VERSION "9"

NS_ :

BS_:

BU_: E115DCU

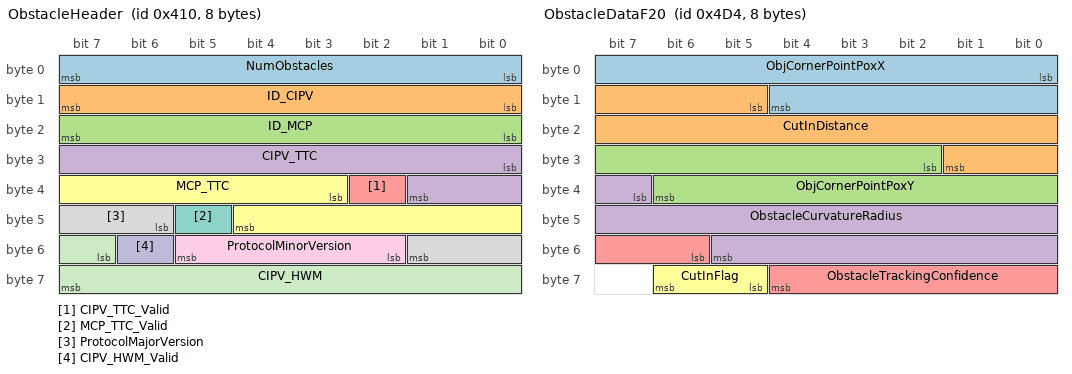
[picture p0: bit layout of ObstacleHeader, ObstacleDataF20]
BO_ 1040 ObstacleHeader: 8 E115DCU
 SG_ NumObstacles : 0|8@1+ (1,0) [0|20] "Counter" Vector__XXX
 SG_ ID_CIPV : 8|8@1+ (1,0) [0|255] "Counter" Vector__XXX
 SG_ ID_MCP : 16|8@1+ (1,0) [0|255] "Counter" Vector__XXX
 SG_ CIPV_TTC : 24|10@1+ (0.01,0) [0|10] "second" Vector__XXX
 SG_ CIPV_TTC_Valid : 34|1@1+ (1,0) [0|1] "bool" Vector__XXX
 SG_ MCP_TTC : 35|10@1+ (0.01,0) [0|10] "second" Vector__XXX
 SG_ MCP_TTC_Valid : 45|1@1+ (1,0) [0|1] "bool" Vector__XXX
 SG_ ProtocolMajorVersion : 46|4@1+ (1,0) [0|15] "Counter" Vector__XXX
 SG_ ProtocolMinorVersion : 50|4@1+ (1,0) [0|15] "Counter" Vector__XXX
 SG_ CIPV_HWM_Valid : 54|1@1+ (1,0) [0|1] "bool" Vector__XXX
 SG_ CIPV_HWM : 55|9@1+ (0.02,0) [0|10.22] "second" Vector__XXX

BO_ 1236 ObstacleDataF20: 8 Vector__XXX
 SG_ ObjCornerPointPoxX : 0|13@1+ (0.0625,-250) [-250|250] "m" Vector__XXX
 SG_ CutInDistance : 13|13@1+ (0.01,-40.96) [-40.96|40.95] "m" Vector__XXX
 SG_ ObjCornerPointPoxY : 26|13@1+ (0.0625,-250) [-250|250] "m" Vector__XXX
 SG_ ObstacleCurvatureRadius : 39|15@1+ (1,-9999) [-9999|9999] "m" Vector__XXX
 SG_ ObstacleTrackingConfidence : 54|7@1+ (1,0) [0|100] "prob" Vector__XXX
 SG_ CutInFlag : 61|2@1+ (1,0) [0|2] "Enum" Vector__XXX

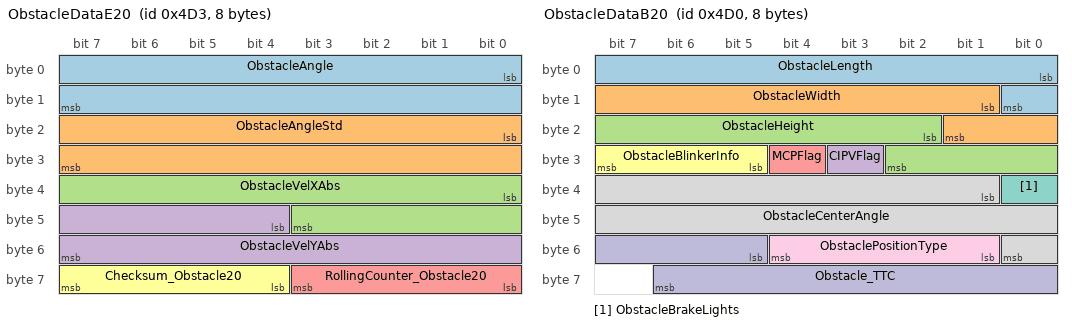
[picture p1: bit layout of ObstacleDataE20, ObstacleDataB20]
BO_ 1235 ObstacleDataE20: 8 E115DCU
 SG_ ObstacleAngle : 0|16@1+ (0.01,-327.68) [-327.68|327.67] "degree"  E115DCU
 SG_ ObstacleAngleStd : 16|16@1+ (0.01,0) [0|327.67] "degree"  E115DCU
 SG_ ObstacleVelXAbs : 32|12@1+ (0.05,-102.4) [-102.4|102.35] "m/sec"  E115DCU
 SG_ ObstacleVelYAbs : 44|12@1+ (0.05,-50) [-50|50] "m/sec"  E115DCU
 SG_ RollingCounter_Obstacle20 : 56|4@1+ (1,0) [0|15] "Counter"  E115DCU
 SG_ Checksum_Obstacle20 : 60|4@1+ (1,0) [0|15] "Counter"  E115DCU

BO_ 1234 ObstacleDataD20: 8 E115DCU
 SG_ ObstaclePosXSTD : 0|13@1+ (0.0625,0) [0|250] "m"  E115DCU
 SG_ ObstaclePosYSTD : 13|13@1+ (0.0625,0) [0|250] "m"  E115DCU
 SG_ ObstacleVelXSTD : 26|12@1+ (0.05,0) [0|102.35] "m/sec"  E115DCU
 SG_ ObstacleVelYSTD : 38|12@1+ (0.05,0) [0|50] "m/sec"  E115DCU
 SG_ ObstacleAccY : 50|10@1+ (0.03,-14.97) [-14.97|14.97] "m/s^2"  E115DCU

BO_ 1233 ObstacleDataC20: 8 E115DCU
 SG_ ObstaclePosX : 0|13@1+ (0.0625,-250) [-250|250] "m"  E115DCU
 SG_ ObstaclePosY : 13|13@1+ (0.0625,-250) [-250|250] "m"  E115DCU
 SG_ ObstacleVelX : 26|12@1+ (0.05,-102.4) [-102.4|102.35] "m/sec"  E115DCU
 SG_ ObstacleVelY : 38|12@1+ (0.05,-50) [-50|50] "m/sec"  E115DCU
 SG_ ObstacleAccX : 50|10@1+ (0.03,-14.97) [-14.97|14.97] "m/s^2"  E115DCU

BO_ 1232 ObstacleDataB20: 8 E115DCU
 SG_ ObstacleLength : 0|9@1+ (0.05,0) [0|25.6] "m"  E115DCU
 SG_ ObstacleWidth : 9|9@1+ (0.02,0) [0|10.24] "m"  E115DCU
 SG_ ObstacleHeight : 18|9@1+ (0.02,0) [0|10.24] "m"  E115DCU
 SG_ CIPVFlag : 27|1@1+ (1,0) [0|1] "bool"  E115DCU
 SG_ MCPFlag : 28|1@1+ (1,0) [0|1] "bool"  E115DCU
 SG_ ObstacleBlinkerInfo : 29|3@1+ (1,0) [0|4] "Enum"  E115DCU
 SG_ ObstacleBrakeLights : 32|1@1+ (1,0) [0|1] "bool"  E115DCU
 SG_ ObstacleCenterAngle : 33|16@1+ (0.01,-327.68) [-327.68|327.67] "degree"  E115DCU
 SG_ ObstaclePositionType : 49|4@1+ (1,0) [0|9] "Enum"  E115DCU
 SG_ Obstacle_TTC : 53|10@1+ (0.01,0) [0|10] "sec"  E115DCU

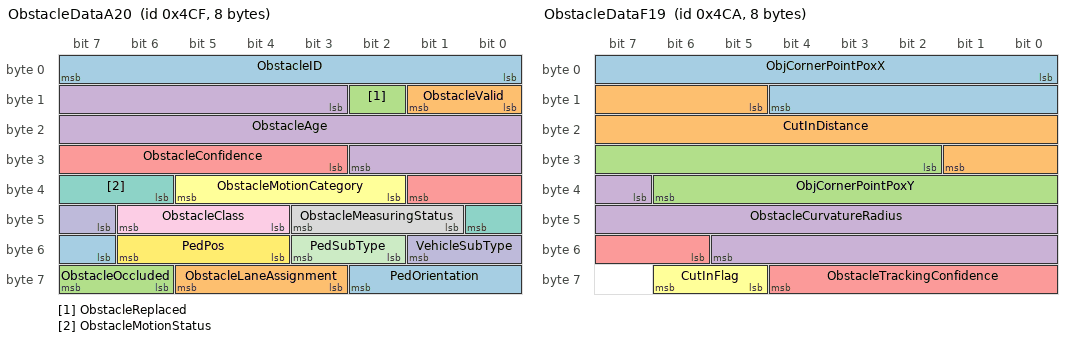
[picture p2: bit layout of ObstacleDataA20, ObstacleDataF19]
BO_ 1231 ObstacleDataA20: 8 E115DCU
 SG_ ObstacleID : 0|8@1+ (1,0) [0|255] "Counter"  E115DCU
 SG_ ObstacleValid : 8|2@1+ (1,0) [0|2] "Enum"  E115DCU
 SG_ ObstacleReplaced : 10|1@1+ (1,0) [0|1] "bool"  E115DCU
 SG_ ObstacleAge : 11|16@1+ (1,0) [0|65535] "Counter"  E115DCU
 SG_ ObstacleConfidence : 27|7@1+ (1,0) [0|100] "prob"  E115DCU
 SG_ ObstacleMotionCategory : 34|4@1+ (1,0) [0|13] "Enum"  E115DCU
 SG_ ObstacleMotionStatus : 38|3@1+ (1,0) [0|7] "Enum"  E115DCU
 SG_ ObstacleMeasuringStatus : 41|3@1+ (1,0) [0|7] "Enum"  E115DCU
 SG_ ObstacleClass : 44|3@1+ (1,0) [0|7] "Enum"  E115DCU
 SG_ VehicleSubType : 47|3@1+ (1,0) [0|7] "Enum"  E115DCU
 SG_ PedSubType : 50|2@1+ (1,0) [0|3] "Enum"  E115DCU
 SG_ PedPos : 52|3@1+ (1,0) [0|7] "Enum"  E115DCU
 SG_ PedOrientation : 55|4@1+ (1,0) [0|9] "Enum"  E115DCU
 SG_ ObstacleLaneAssignment : 59|3@1+ (1,0) [0|5] "Enum"  E115DCU
 SG_ ObstacleOccluded : 62|2@1+ (1,0) [0|3] "Enum"  E115DCU

BO_ 1226 ObstacleDataF19: 8 Vector__XXX
 SG_ ObjCornerPointPoxX : 0|13@1+ (0.0625,-250) [-250|250] "m" Vector__XXX
 SG_ CutInDistance : 13|13@1+ (0.01,-40.96) [-40.96|40.95] "m" Vector__XXX
 SG_ ObjCornerPointPoxY : 26|13@1+ (0.0625,-250) [-250|250] "m" Vector__XXX
 SG_ ObstacleCurvatureRadius : 39|15@1+ (1,-9999) [-9999|9999] "m" Vector__XXX
 SG_ ObstacleTrackingConfidence : 54|7@1+ (1,0) [0|100] "prob" Vector__XXX
 SG_ CutInFlag : 61|2@1+ (1,0) [0|2] "Enum" Vector__XXX

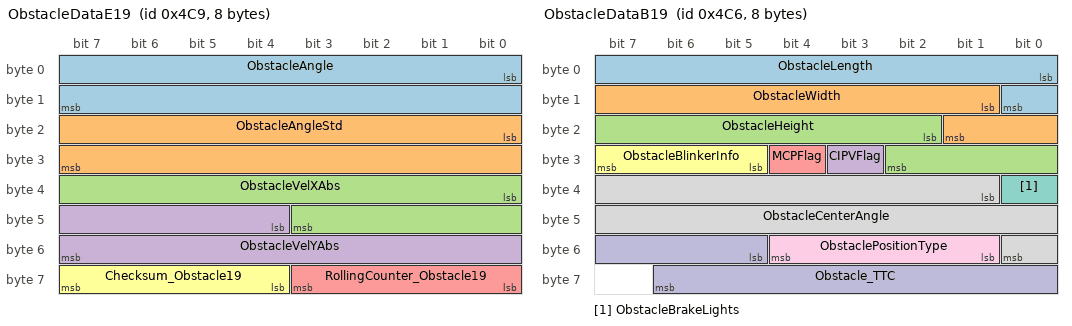
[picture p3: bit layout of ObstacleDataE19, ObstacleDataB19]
BO_ 1225 ObstacleDataE19: 8 E115DCU
 SG_ ObstacleAngle : 0|16@1+ (0.01,-327.68) [-327.68|327.67] "degree"  E115DCU
 SG_ ObstacleAngleStd : 16|16@1+ (0.01,0) [0|327.67] "degree"  E115DCU
 SG_ ObstacleVelXAbs : 32|12@1+ (0.05,-102.4) [-102.4|102.35] "m/sec"  E115DCU
 SG_ ObstacleVelYAbs : 44|12@1+ (0.05,-50) [-50|50] "m/sec"  E115DCU
 SG_ RollingCounter_Obstacle19 : 56|4@1+ (1,0) [0|15] "Counter"  E115DCU
 SG_ Checksum_Obstacle19 : 60|4@1+ (1,0) [0|15] "Counter"  E115DCU

BO_ 1224 ObstacleDataD19: 8 E115DCU
 SG_ ObstaclePosXSTD : 0|13@1+ (0.0625,0) [0|250] "m"  E115DCU
 SG_ ObstaclePosYSTD : 13|13@1+ (0.0625,0) [0|250] "m"  E115DCU
 SG_ ObstacleVelXSTD : 26|12@1+ (0.05,0) [0|102.35] "m/sec"  E115DCU
 SG_ ObstacleVelYSTD : 38|12@1+ (0.05,0) [0|50] "m/sec"  E115DCU
 SG_ ObstacleAccY : 50|10@1+ (0.03,-14.97) [-14.97|14.97] "m/s^2"  E115DCU

BO_ 1223 ObstacleDataC19: 8 E115DCU
 SG_ ObstaclePosX : 0|13@1+ (0.0625,-250) [-250|250] "m"  E115DCU
 SG_ ObstaclePosY : 13|13@1+ (0.0625,-250) [-250|250] "m"  E115DCU
 SG_ ObstacleVelX : 26|12@1+ (0.05,-102.4) [-102.4|102.35] "m/sec"  E115DCU
 SG_ ObstacleVelY : 38|12@1+ (0.05,-50) [-50|50] "m/sec"  E115DCU
 SG_ ObstacleAccX : 50|10@1+ (0.03,-14.97) [-14.97|14.97] "m/s^2"  E115DCU

BO_ 1222 ObstacleDataB19: 8 E115DCU
 SG_ ObstacleLength : 0|9@1+ (0.05,0) [0|25.6] "m"  E115DCU
 SG_ ObstacleWidth : 9|9@1+ (0.02,0) [0|10.24] "m"  E115DCU
 SG_ ObstacleHeight : 18|9@1+ (0.02,0) [0|10.24] "m"  E115DCU
 SG_ CIPVFlag : 27|1@1+ (1,0) [0|1] "bool"  E115DCU
 SG_ MCPFlag : 28|1@1+ (1,0) [0|1] "bool"  E115DCU
 SG_ ObstacleBlinkerInfo : 29|3@1+ (1,0) [0|4] "Enum"  E115DCU
 SG_ ObstacleBrakeLights : 32|1@1+ (1,0) [0|1] "bool"  E115DCU
 SG_ ObstacleCenterAngle : 33|16@1+ (0.01,-327.68) [-327.68|327.67] "degree"  E115DCU
 SG_ ObstaclePositionType : 49|4@1+ (1,0) [0|9] "Enum"  E115DCU
 SG_ Obstacle_TTC : 53|10@1+ (0.01,0) [0|10] "sec"  E115DCU

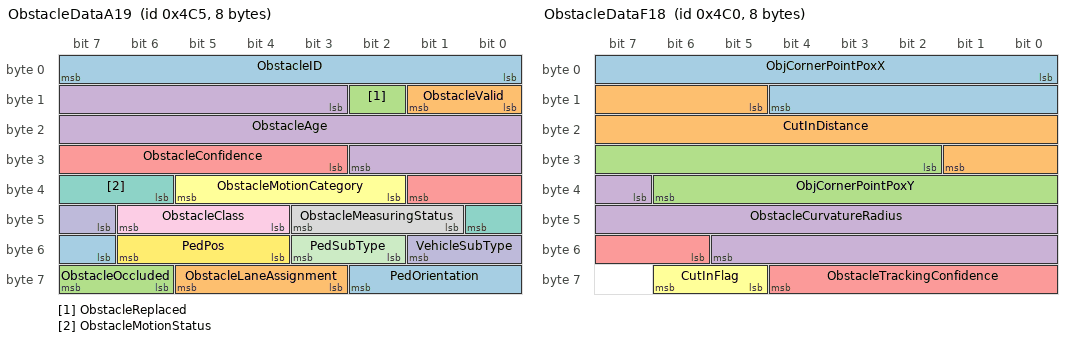
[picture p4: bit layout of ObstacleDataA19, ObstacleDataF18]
BO_ 1221 ObstacleDataA19: 8 E115DCU
 SG_ ObstacleID : 0|8@1+ (1,0) [0|255] "Counter"  E115DCU
 SG_ ObstacleValid : 8|2@1+ (1,0) [0|2] "Enum"  E115DCU
 SG_ ObstacleReplaced : 10|1@1+ (1,0) [0|1] "bool"  E115DCU
 SG_ ObstacleAge : 11|16@1+ (1,0) [0|65535] "Counter"  E115DCU
 SG_ ObstacleConfidence : 27|7@1+ (1,0) [0|100] "prob"  E115DCU
 SG_ ObstacleMotionCategory : 34|4@1+ (1,0) [0|13] "Enum"  E115DCU
 SG_ ObstacleMotionStatus : 38|3@1+ (1,0) [0|7] "Enum"  E115DCU
 SG_ ObstacleMeasuringStatus : 41|3@1+ (1,0) [0|7] "Enum"  E115DCU
 SG_ ObstacleClass : 44|3@1+ (1,0) [0|7] "Enum"  E115DCU
 SG_ VehicleSubType : 47|3@1+ (1,0) [0|7] "Enum"  E115DCU
 SG_ PedSubType : 50|2@1+ (1,0) [0|3] "Enum"  E115DCU
 SG_ PedPos : 52|3@1+ (1,0) [0|7] "Enum"  E115DCU
 SG_ PedOrientation : 55|4@1+ (1,0) [0|9] "Enum"  E115DCU
 SG_ ObstacleLaneAssignment : 59|3@1+ (1,0) [0|5] "Enum"  E115DCU
 SG_ ObstacleOccluded : 62|2@1+ (1,0) [0|3] "Enum"  E115DCU

BO_ 1216 ObstacleDataF18: 8 Vector__XXX
 SG_ ObjCornerPointPoxX : 0|13@1+ (0.0625,-250) [-250|250] "m" Vector__XXX
 SG_ CutInDistance : 13|13@1+ (0.01,-40.96) [-40.96|40.95] "m" Vector__XXX
 SG_ ObjCornerPointPoxY : 26|13@1+ (0.0625,-250) [-250|250] "m" Vector__XXX
 SG_ ObstacleCurvatureRadius : 39|15@1+ (1,-9999) [-9999|9999] "m" Vector__XXX
 SG_ ObstacleTrackingConfidence : 54|7@1+ (1,0) [0|100] "prob" Vector__XXX
 SG_ CutInFlag : 61|2@1+ (1,0) [0|2] "Enum" Vector__XXX

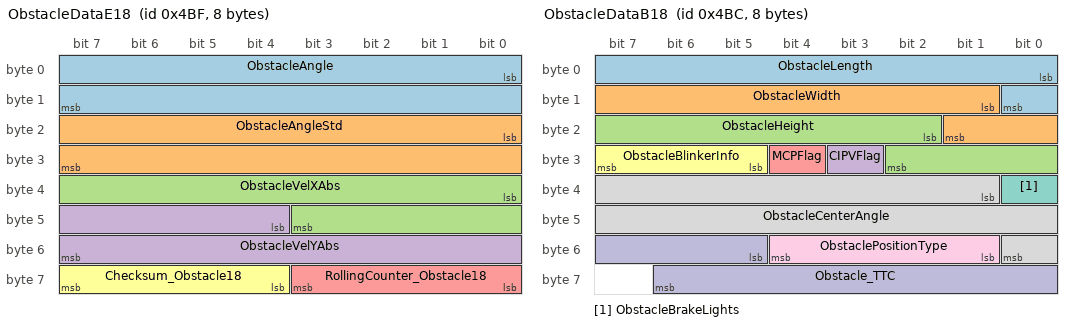
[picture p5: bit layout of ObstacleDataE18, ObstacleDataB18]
BO_ 1215 ObstacleDataE18: 8 E115DCU
 SG_ ObstacleAngle : 0|16@1+ (0.01,-327.68) [-327.68|327.67] "degree"  E115DCU
 SG_ ObstacleAngleStd : 16|16@1+ (0.01,0) [0|327.67] "degree"  E115DCU
 SG_ ObstacleVelXAbs : 32|12@1+ (0.05,-102.4) [-102.4|102.35] "m/sec"  E115DCU
 SG_ ObstacleVelYAbs : 44|12@1+ (0.05,-50) [-50|50] "m/sec"  E115DCU
 SG_ RollingCounter_Obstacle18 : 56|4@1+ (1,0) [0|15] "Counter"  E115DCU
 SG_ Checksum_Obstacle18 : 60|4@1+ (1,0) [0|15] "Counter"  E115DCU

BO_ 1214 ObstacleDataD18: 8 E115DCU
 SG_ ObstaclePosXSTD : 0|13@1+ (0.0625,0) [0|250] "m"  E115DCU
 SG_ ObstaclePosYSTD : 13|13@1+ (0.0625,0) [0|250] "m"  E115DCU
 SG_ ObstacleVelXSTD : 26|12@1+ (0.05,0) [0|102.35] "m/sec"  E115DCU
 SG_ ObstacleVelYSTD : 38|12@1+ (0.05,0) [0|50] "m/sec"  E115DCU
 SG_ ObstacleAccY : 50|10@1+ (0.03,-14.97) [-14.97|14.97] "m/s^2"  E115DCU

BO_ 1213 ObstacleDataC18: 8 E115DCU
 SG_ ObstaclePosX : 0|13@1+ (0.0625,-250) [-250|250] "m"  E115DCU
 SG_ ObstaclePosY : 13|13@1+ (0.0625,-250) [-250|250] "m"  E115DCU
 SG_ ObstacleVelX : 26|12@1+ (0.05,-102.4) [-102.4|102.35] "m/sec"  E115DCU
 SG_ ObstacleVelY : 38|12@1+ (0.05,-50) [-50|50] "m/sec"  E115DCU
 SG_ ObstacleAccX : 50|10@1+ (0.03,-14.97) [-14.97|14.97] "m/s^2"  E115DCU

BO_ 1212 ObstacleDataB18: 8 E115DCU
 SG_ ObstacleLength : 0|9@1+ (0.05,0) [0|25.6] "m"  E115DCU
 SG_ ObstacleWidth : 9|9@1+ (0.02,0) [0|10.24] "m"  E115DCU
 SG_ ObstacleHeight : 18|9@1+ (0.02,0) [0|10.24] "m"  E115DCU
 SG_ CIPVFlag : 27|1@1+ (1,0) [0|1] "bool"  E115DCU
 SG_ MCPFlag : 28|1@1+ (1,0) [0|1] "bool"  E115DCU
 SG_ ObstacleBlinkerInfo : 29|3@1+ (1,0) [0|4] "Enum"  E115DCU
 SG_ ObstacleBrakeLights : 32|1@1+ (1,0) [0|1] "bool"  E115DCU
 SG_ ObstacleCenterAngle : 33|16@1+ (0.01,-327.68) [-327.68|327.67] "degree"  E115DCU
 SG_ ObstaclePositionType : 49|4@1+ (1,0) [0|9] "Enum"  E115DCU
 SG_ Obstacle_TTC : 53|10@1+ (0.01,0) [0|10] "sec"  E115DCU

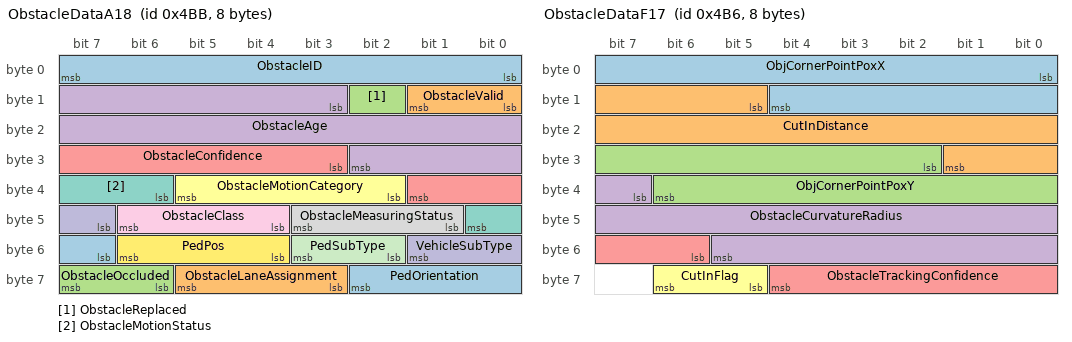
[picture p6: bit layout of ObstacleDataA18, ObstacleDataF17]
BO_ 1211 ObstacleDataA18: 8 E115DCU
 SG_ ObstacleID : 0|8@1+ (1,0) [0|255] "Counter"  E115DCU
 SG_ ObstacleValid : 8|2@1+ (1,0) [0|2] "Enum"  E115DCU
 SG_ ObstacleReplaced : 10|1@1+ (1,0) [0|1] "bool"  E115DCU
 SG_ ObstacleAge : 11|16@1+ (1,0) [0|65535] "Counter"  E115DCU
 SG_ ObstacleConfidence : 27|7@1+ (1,0) [0|100] "prob"  E115DCU
 SG_ ObstacleMotionCategory : 34|4@1+ (1,0) [0|13] "Enum"  E115DCU
 SG_ ObstacleMotionStatus : 38|3@1+ (1,0) [0|7] "Enum"  E115DCU
 SG_ ObstacleMeasuringStatus : 41|3@1+ (1,0) [0|7] "Enum"  E115DCU
 SG_ ObstacleClass : 44|3@1+ (1,0) [0|7] "Enum"  E115DCU
 SG_ VehicleSubType : 47|3@1+ (1,0) [0|7] "Enum"  E115DCU
 SG_ PedSubType : 50|2@1+ (1,0) [0|3] "Enum"  E115DCU
 SG_ PedPos : 52|3@1+ (1,0) [0|7] "Enum"  E115DCU
 SG_ PedOrientation : 55|4@1+ (1,0) [0|9] "Enum"  E115DCU
 SG_ ObstacleLaneAssignment : 59|3@1+ (1,0) [0|5] "Enum"  E115DCU
 SG_ ObstacleOccluded : 62|2@1+ (1,0) [0|3] "Enum"  E115DCU

BO_ 1206 ObstacleDataF17: 8 Vector__XXX
 SG_ ObjCornerPointPoxX : 0|13@1+ (0.0625,-250) [-250|250] "m" Vector__XXX
 SG_ CutInDistance : 13|13@1+ (0.01,-40.96) [-40.96|40.95] "m" Vector__XXX
 SG_ ObjCornerPointPoxY : 26|13@1+ (0.0625,-250) [-250|250] "m" Vector__XXX
 SG_ ObstacleCurvatureRadius : 39|15@1+ (1,-9999) [-9999|9999] "m" Vector__XXX
 SG_ ObstacleTrackingConfidence : 54|7@1+ (1,0) [0|100] "prob" Vector__XXX
 SG_ CutInFlag : 61|2@1+ (1,0) [0|2] "Enum" Vector__XXX

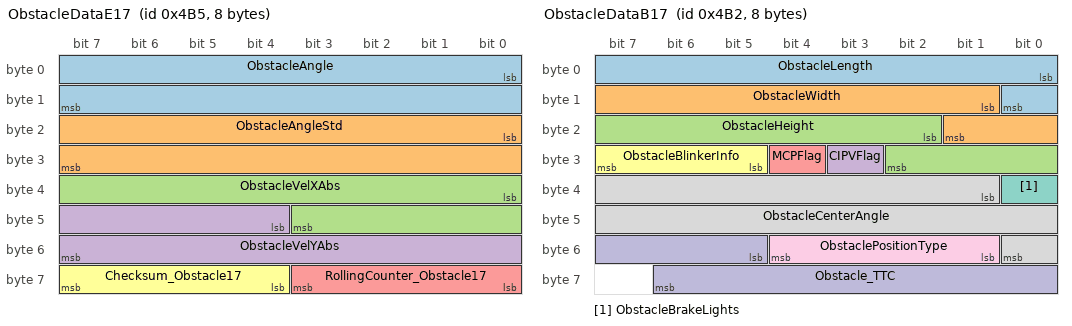
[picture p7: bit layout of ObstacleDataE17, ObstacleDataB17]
BO_ 1205 ObstacleDataE17: 8 E115DCU
 SG_ ObstacleAngle : 0|16@1+ (0.01,-327.68) [-327.68|327.67] "degree"  E115DCU
 SG_ ObstacleAngleStd : 16|16@1+ (0.01,0) [0|327.67] "degree"  E115DCU
 SG_ ObstacleVelXAbs : 32|12@1+ (0.05,-102.4) [-102.4|102.35] "m/sec"  E115DCU
 SG_ ObstacleVelYAbs : 44|12@1+ (0.05,-50) [-50|50] "m/sec"  E115DCU
 SG_ RollingCounter_Obstacle17 : 56|4@1+ (1,0) [0|15] "Counter"  E115DCU
 SG_ Checksum_Obstacle17 : 60|4@1+ (1,0) [0|15] "Counter"  E115DCU

BO_ 1204 ObstacleDataD17: 8 E115DCU
 SG_ ObstaclePosXSTD : 0|13@1+ (0.0625,0) [0|250] "m"  E115DCU
 SG_ ObstaclePosYSTD : 13|13@1+ (0.0625,0) [0|250] "m"  E115DCU
 SG_ ObstacleVelXSTD : 26|12@1+ (0.05,0) [0|102.35] "m/sec"  E115DCU
 SG_ ObstacleVelYSTD : 38|12@1+ (0.05,0) [0|50] "m/sec"  E115DCU
 SG_ ObstacleAccY : 50|10@1+ (0.03,-14.97) [-14.97|14.97] "m/s^2"  E115DCU

BO_ 1203 ObstacleDataC17: 8 E115DCU
 SG_ ObstaclePosX : 0|13@1+ (0.0625,-250) [-250|250] "m"  E115DCU
 SG_ ObstaclePosY : 13|13@1+ (0.0625,-250) [-250|250] "m"  E115DCU
 SG_ ObstacleVelX : 26|12@1+ (0.05,-102.4) [-102.4|102.35] "m/sec"  E115DCU
 SG_ ObstacleVelY : 38|12@1+ (0.05,-50) [-50|50] "m/sec"  E115DCU
 SG_ ObstacleAccX : 50|10@1+ (0.03,-14.97) [-14.97|14.97] "m/s^2"  E115DCU

BO_ 1202 ObstacleDataB17: 8 E115DCU
 SG_ ObstacleLength : 0|9@1+ (0.05,0) [0|25.6] "m"  E115DCU
 SG_ ObstacleWidth : 9|9@1+ (0.02,0) [0|10.24] "m"  E115DCU
 SG_ ObstacleHeight : 18|9@1+ (0.02,0) [0|10.24] "m"  E115DCU
 SG_ CIPVFlag : 27|1@1+ (1,0) [0|1] "bool"  E115DCU
 SG_ MCPFlag : 28|1@1+ (1,0) [0|1] "bool"  E115DCU
 SG_ ObstacleBlinkerInfo : 29|3@1+ (1,0) [0|4] "Enum"  E115DCU
 SG_ ObstacleBrakeLights : 32|1@1+ (1,0) [0|1] "bool"  E115DCU
 SG_ ObstacleCenterAngle : 33|16@1+ (0.01,-327.68) [-327.68|327.67] "degree"  E115DCU
 SG_ ObstaclePositionType : 49|4@1+ (1,0) [0|9] "Enum"  E115DCU
 SG_ Obstacle_TTC : 53|10@1+ (0.01,0) [0|10] "sec"  E115DCU

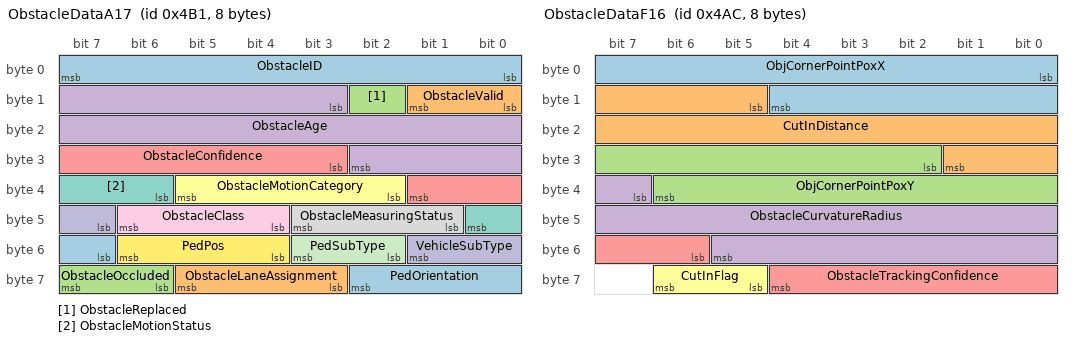
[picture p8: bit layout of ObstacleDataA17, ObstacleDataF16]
BO_ 1201 ObstacleDataA17: 8 E115DCU
 SG_ ObstacleID : 0|8@1+ (1,0) [0|255] "Counter"  E115DCU
 SG_ ObstacleValid : 8|2@1+ (1,0) [0|2] "Enum"  E115DCU
 SG_ ObstacleReplaced : 10|1@1+ (1,0) [0|1] "bool"  E115DCU
 SG_ ObstacleAge : 11|16@1+ (1,0) [0|65535] "Counter"  E115DCU
 SG_ ObstacleConfidence : 27|7@1+ (1,0) [0|100] "prob"  E115DCU
 SG_ ObstacleMotionCategory : 34|4@1+ (1,0) [0|13] "Enum"  E115DCU
 SG_ ObstacleMotionStatus : 38|3@1+ (1,0) [0|7] "Enum"  E115DCU
 SG_ ObstacleMeasuringStatus : 41|3@1+ (1,0) [0|7] "Enum"  E115DCU
 SG_ ObstacleClass : 44|3@1+ (1,0) [0|7] "Enum"  E115DCU
 SG_ VehicleSubType : 47|3@1+ (1,0) [0|7] "Enum"  E115DCU
 SG_ PedSubType : 50|2@1+ (1,0) [0|3] "Enum"  E115DCU
 SG_ PedPos : 52|3@1+ (1,0) [0|7] "Enum"  E115DCU
 SG_ PedOrientation : 55|4@1+ (1,0) [0|9] "Enum"  E115DCU
 SG_ ObstacleLaneAssignment : 59|3@1+ (1,0) [0|5] "Enum"  E115DCU
 SG_ ObstacleOccluded : 62|2@1+ (1,0) [0|3] "Enum"  E115DCU

BO_ 1196 ObstacleDataF16: 8 Vector__XXX
 SG_ ObjCornerPointPoxX : 0|13@1+ (0.0625,-250) [-250|250] "m" Vector__XXX
 SG_ CutInDistance : 13|13@1+ (0.01,-40.96) [-40.96|40.95] "m" Vector__XXX
 SG_ ObjCornerPointPoxY : 26|13@1+ (0.0625,-250) [-250|250] "m" Vector__XXX
 SG_ ObstacleCurvatureRadius : 39|15@1+ (1,-9999) [-9999|9999] "m" Vector__XXX
 SG_ ObstacleTrackingConfidence : 54|7@1+ (1,0) [0|100] "prob" Vector__XXX
 SG_ CutInFlag : 61|2@1+ (1,0) [0|2] "Enum" Vector__XXX

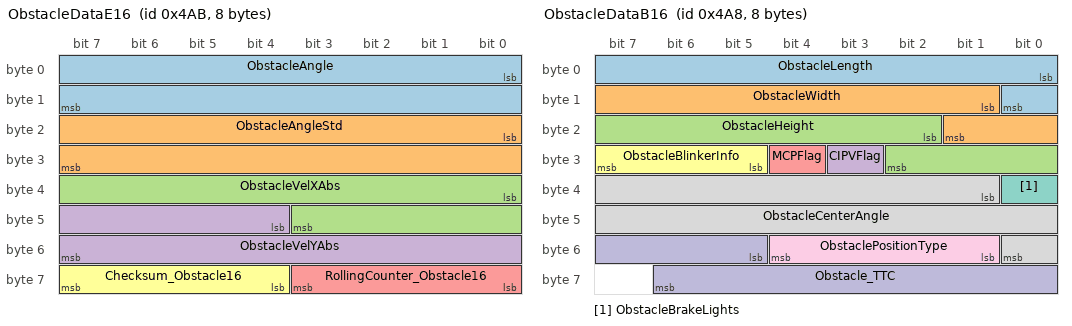
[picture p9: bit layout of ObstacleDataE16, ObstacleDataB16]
BO_ 1195 ObstacleDataE16: 8 E115DCU
 SG_ ObstacleAngle : 0|16@1+ (0.01,-327.68) [-327.68|327.67] "degree"  E115DCU
 SG_ ObstacleAngleStd : 16|16@1+ (0.01,0) [0|327.67] "degree"  E115DCU
 SG_ ObstacleVelXAbs : 32|12@1+ (0.05,-102.4) [-102.4|102.35] "m/sec"  E115DCU
 SG_ ObstacleVelYAbs : 44|12@1+ (0.05,-50) [-50|50] "m/sec"  E115DCU
 SG_ RollingCounter_Obstacle16 : 56|4@1+ (1,0) [0|15] "Counter"  E115DCU
 SG_ Checksum_Obstacle16 : 60|4@1+ (1,0) [0|15] "Counter"  E115DCU

BO_ 1194 ObstacleDataD16: 8 E115DCU
 SG_ ObstaclePosXSTD : 0|13@1+ (0.0625,0) [0|250] "m"  E115DCU
 SG_ ObstaclePosYSTD : 13|13@1+ (0.0625,0) [0|250] "m"  E115DCU
 SG_ ObstacleVelXSTD : 26|12@1+ (0.05,0) [0|102.35] "m/sec"  E115DCU
 SG_ ObstacleVelYSTD : 38|12@1+ (0.05,0) [0|50] "m/sec"  E115DCU
 SG_ ObstacleAccY : 50|10@1+ (0.03,-14.97) [-14.97|14.97] "m/s^2"  E115DCU

BO_ 1193 ObstacleDataC16: 8 E115DCU
 SG_ ObstaclePosX : 0|13@1+ (0.0625,-250) [-250|250] "m"  E115DCU
 SG_ ObstaclePosY : 13|13@1+ (0.0625,-250) [-250|250] "m"  E115DCU
 SG_ ObstacleVelX : 26|12@1+ (0.05,-102.4) [-102.4|102.35] "m/sec"  E115DCU
 SG_ ObstacleVelY : 38|12@1+ (0.05,-50) [-50|50] "m/sec"  E115DCU
 SG_ ObstacleAccX : 50|10@1+ (0.03,-14.97) [-14.97|14.97] "m/s^2"  E115DCU

BO_ 1192 ObstacleDataB16: 8 E115DCU
 SG_ ObstacleLength : 0|9@1+ (0.05,0) [0|25.6] "m"  E115DCU
 SG_ ObstacleWidth : 9|9@1+ (0.02,0) [0|10.24] "m"  E115DCU
 SG_ ObstacleHeight : 18|9@1+ (0.02,0) [0|10.24] "m"  E115DCU
 SG_ CIPVFlag : 27|1@1+ (1,0) [0|1] "bool"  E115DCU
 SG_ MCPFlag : 28|1@1+ (1,0) [0|1] "bool"  E115DCU
 SG_ ObstacleBlinkerInfo : 29|3@1+ (1,0) [0|4] "Enum"  E115DCU
 SG_ ObstacleBrakeLights : 32|1@1+ (1,0) [0|1] "bool"  E115DCU
 SG_ ObstacleCenterAngle : 33|16@1+ (0.01,-327.68) [-327.68|327.67] "degree"  E115DCU
 SG_ ObstaclePositionType : 49|4@1+ (1,0) [0|9] "Enum"  E115DCU
 SG_ Obstacle_TTC : 53|10@1+ (0.01,0) [0|10] "sec"  E115DCU

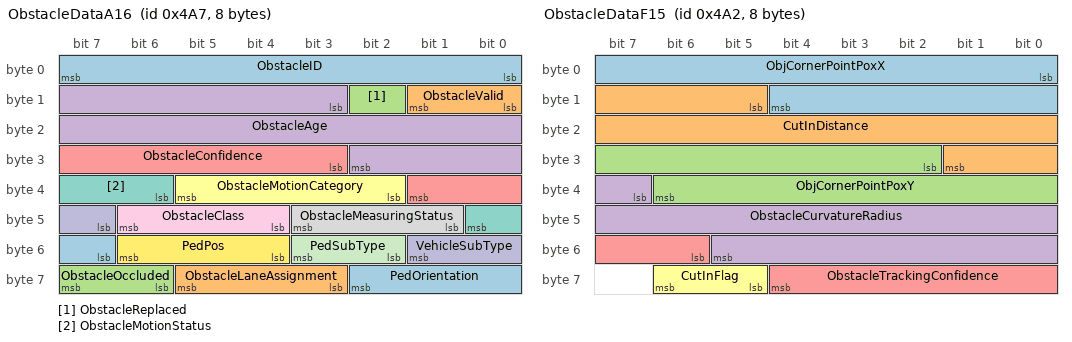
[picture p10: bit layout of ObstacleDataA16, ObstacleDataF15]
BO_ 1191 ObstacleDataA16: 8 E115DCU
 SG_ ObstacleID : 0|8@1+ (1,0) [0|255] "Counter"  E115DCU
 SG_ ObstacleValid : 8|2@1+ (1,0) [0|2] "Enum"  E115DCU
 SG_ ObstacleReplaced : 10|1@1+ (1,0) [0|1] "bool"  E115DCU
 SG_ ObstacleAge : 11|16@1+ (1,0) [0|65535] "Counter"  E115DCU
 SG_ ObstacleConfidence : 27|7@1+ (1,0) [0|100] "prob"  E115DCU
 SG_ ObstacleMotionCategory : 34|4@1+ (1,0) [0|13] "Enum"  E115DCU
 SG_ ObstacleMotionStatus : 38|3@1+ (1,0) [0|7] "Enum"  E115DCU
 SG_ ObstacleMeasuringStatus : 41|3@1+ (1,0) [0|7] "Enum"  E115DCU
 SG_ ObstacleClass : 44|3@1+ (1,0) [0|7] "Enum"  E115DCU
 SG_ VehicleSubType : 47|3@1+ (1,0) [0|7] "Enum"  E115DCU
 SG_ PedSubType : 50|2@1+ (1,0) [0|3] "Enum"  E115DCU
 SG_ PedPos : 52|3@1+ (1,0) [0|7] "Enum"  E115DCU
 SG_ PedOrientation : 55|4@1+ (1,0) [0|9] "Enum"  E115DCU
 SG_ ObstacleLaneAssignment : 59|3@1+ (1,0) [0|5] "Enum"  E115DCU
 SG_ ObstacleOccluded : 62|2@1+ (1,0) [0|3] "Enum"  E115DCU

BO_ 1186 ObstacleDataF15: 8 Vector__XXX
 SG_ ObjCornerPointPoxX : 0|13@1+ (0.0625,-250) [-250|250] "m" Vector__XXX
 SG_ CutInDistance : 13|13@1+ (0.01,-40.96) [-40.96|40.95] "m" Vector__XXX
 SG_ ObjCornerPointPoxY : 26|13@1+ (0.0625,-250) [-250|250] "m" Vector__XXX
 SG_ ObstacleCurvatureRadius : 39|15@1+ (1,-9999) [-9999|9999] "m" Vector__XXX
 SG_ ObstacleTrackingConfidence : 54|7@1+ (1,0) [0|100] "prob" Vector__XXX
 SG_ CutInFlag : 61|2@1+ (1,0) [0|2] "Enum" Vector__XXX

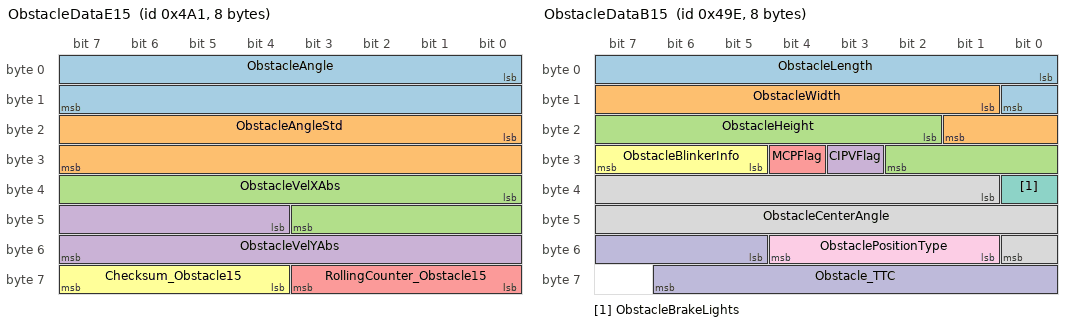
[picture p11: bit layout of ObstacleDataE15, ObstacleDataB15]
BO_ 1185 ObstacleDataE15: 8 E115DCU
 SG_ ObstacleAngle : 0|16@1+ (0.01,-327.68) [-327.68|327.67] "degree"  E115DCU
 SG_ ObstacleAngleStd : 16|16@1+ (0.01,0) [0|327.67] "degree"  E115DCU
 SG_ ObstacleVelXAbs : 32|12@1+ (0.05,-102.4) [-102.4|102.35] "m/sec"  E115DCU
 SG_ ObstacleVelYAbs : 44|12@1+ (0.05,-50) [-50|50] "m/sec"  E115DCU
 SG_ RollingCounter_Obstacle15 : 56|4@1+ (1,0) [0|15] "Counter"  E115DCU
 SG_ Checksum_Obstacle15 : 60|4@1+ (1,0) [0|15] "Counter"  E115DCU

BO_ 1184 ObstacleDataD15: 8 E115DCU
 SG_ ObstaclePosXSTD : 0|13@1+ (0.0625,0) [0|250] "m"  E115DCU
 SG_ ObstaclePosYSTD : 13|13@1+ (0.0625,0) [0|250] "m"  E115DCU
 SG_ ObstacleVelXSTD : 26|12@1+ (0.05,0) [0|102.35] "m/sec"  E115DCU
 SG_ ObstacleVelYSTD : 38|12@1+ (0.05,0) [0|50] "m/sec"  E115DCU
 SG_ ObstacleAccY : 50|10@1+ (0.03,-14.97) [-14.97|14.97] "m/s^2"  E115DCU

BO_ 1183 ObstacleDataC15: 8 E115DCU
 SG_ ObstaclePosX : 0|13@1+ (0.0625,-250) [-250|250] "m"  E115DCU
 SG_ ObstaclePosY : 13|13@1+ (0.0625,-250) [-250|250] "m"  E115DCU
 SG_ ObstacleVelX : 26|12@1+ (0.05,-102.4) [-102.4|102.35] "m/sec"  E115DCU
 SG_ ObstacleVelY : 38|12@1+ (0.05,-50) [-50|50] "m/sec"  E115DCU
 SG_ ObstacleAccX : 50|10@1+ (0.03,-14.97) [-14.97|14.97] "m/s^2"  E115DCU

BO_ 1182 ObstacleDataB15: 8 E115DCU
 SG_ ObstacleLength : 0|9@1+ (0.05,0) [0|25.6] "m"  E115DCU
 SG_ ObstacleWidth : 9|9@1+ (0.02,0) [0|10.24] "m"  E115DCU
 SG_ ObstacleHeight : 18|9@1+ (0.02,0) [0|10.24] "m"  E115DCU
 SG_ CIPVFlag : 27|1@1+ (1,0) [0|1] "bool"  E115DCU
 SG_ MCPFlag : 28|1@1+ (1,0) [0|1] "bool"  E115DCU
 SG_ ObstacleBlinkerInfo : 29|3@1+ (1,0) [0|4] "Enum"  E115DCU
 SG_ ObstacleBrakeLights : 32|1@1+ (1,0) [0|1] "bool"  E115DCU
 SG_ ObstacleCenterAngle : 33|16@1+ (0.01,-327.68) [-327.68|327.67] "degree"  E115DCU
 SG_ ObstaclePositionType : 49|4@1+ (1,0) [0|9] "Enum"  E115DCU
 SG_ Obstacle_TTC : 53|10@1+ (0.01,0) [0|10] "sec"  E115DCU

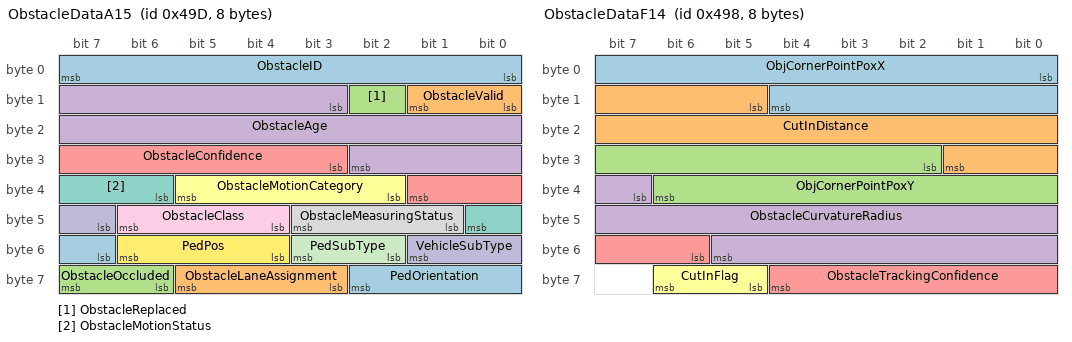
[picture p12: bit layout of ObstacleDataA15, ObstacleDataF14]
BO_ 1181 ObstacleDataA15: 8 E115DCU
 SG_ ObstacleID : 0|8@1+ (1,0) [0|255] "Counter"  E115DCU
 SG_ ObstacleValid : 8|2@1+ (1,0) [0|2] "Enum"  E115DCU
 SG_ ObstacleReplaced : 10|1@1+ (1,0) [0|1] "bool"  E115DCU
 SG_ ObstacleAge : 11|16@1+ (1,0) [0|65535] "Counter"  E115DCU
 SG_ ObstacleConfidence : 27|7@1+ (1,0) [0|100] "prob"  E115DCU
 SG_ ObstacleMotionCategory : 34|4@1+ (1,0) [0|13] "Enum"  E115DCU
 SG_ ObstacleMotionStatus : 38|3@1+ (1,0) [0|7] "Enum"  E115DCU
 SG_ ObstacleMeasuringStatus : 41|3@1+ (1,0) [0|7] "Enum"  E115DCU
 SG_ ObstacleClass : 44|3@1+ (1,0) [0|7] "Enum"  E115DCU
 SG_ VehicleSubType : 47|3@1+ (1,0) [0|7] "Enum"  E115DCU
 SG_ PedSubType : 50|2@1+ (1,0) [0|3] "Enum"  E115DCU
 SG_ PedPos : 52|3@1+ (1,0) [0|7] "Enum"  E115DCU
 SG_ PedOrientation : 55|4@1+ (1,0) [0|9] "Enum"  E115DCU
 SG_ ObstacleLaneAssignment : 59|3@1+ (1,0) [0|5] "Enum"  E115DCU
 SG_ ObstacleOccluded : 62|2@1+ (1,0) [0|3] "Enum"  E115DCU

BO_ 1176 ObstacleDataF14: 8 Vector__XXX
 SG_ ObjCornerPointPoxX : 0|13@1+ (0.0625,-250) [-250|250] "m" Vector__XXX
 SG_ CutInDistance : 13|13@1+ (0.01,-40.96) [-40.96|40.95] "m" Vector__XXX
 SG_ ObjCornerPointPoxY : 26|13@1+ (0.0625,-250) [-250|250] "m" Vector__XXX
 SG_ ObstacleCurvatureRadius : 39|15@1+ (1,-9999) [-9999|9999] "m" Vector__XXX
 SG_ ObstacleTrackingConfidence : 54|7@1+ (1,0) [0|100] "prob" Vector__XXX
 SG_ CutInFlag : 61|2@1+ (1,0) [0|2] "Enum" Vector__XXX

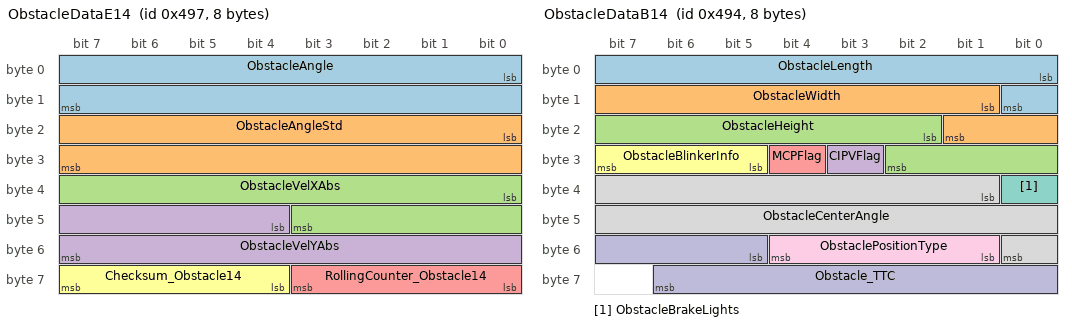
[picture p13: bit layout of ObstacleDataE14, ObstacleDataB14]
BO_ 1175 ObstacleDataE14: 8 E115DCU
 SG_ ObstacleAngle : 0|16@1+ (0.01,-327.68) [-327.68|327.67] "degree"  E115DCU
 SG_ ObstacleAngleStd : 16|16@1+ (0.01,0) [0|327.67] "degree"  E115DCU
 SG_ ObstacleVelXAbs : 32|12@1+ (0.05,-102.4) [-102.4|102.35] "m/sec"  E115DCU
 SG_ ObstacleVelYAbs : 44|12@1+ (0.05,-50) [-50|50] "m/sec"  E115DCU
 SG_ RollingCounter_Obstacle14 : 56|4@1+ (1,0) [0|15] "Counter"  E115DCU
 SG_ Checksum_Obstacle14 : 60|4@1+ (1,0) [0|15] "Counter"  E115DCU

BO_ 1174 ObstacleDataD14: 8 E115DCU
 SG_ ObstaclePosXSTD : 0|13@1+ (0.0625,0) [0|250] "m"  E115DCU
 SG_ ObstaclePosYSTD : 13|13@1+ (0.0625,0) [0|250] "m"  E115DCU
 SG_ ObstacleVelXSTD : 26|12@1+ (0.05,0) [0|102.35] "m/sec"  E115DCU
 SG_ ObstacleVelYSTD : 38|12@1+ (0.05,0) [0|50] "m/sec"  E115DCU
 SG_ ObstacleAccY : 50|10@1+ (0.03,-14.97) [-14.97|14.97] "m/s^2"  E115DCU

BO_ 1173 ObstacleDataC14: 8 E115DCU
 SG_ ObstaclePosX : 0|13@1+ (0.0625,-250) [-250|250] "m"  E115DCU
 SG_ ObstaclePosY : 13|13@1+ (0.0625,-250) [-250|250] "m"  E115DCU
 SG_ ObstacleVelX : 26|12@1+ (0.05,-102.4) [-102.4|102.35] "m/sec"  E115DCU
 SG_ ObstacleVelY : 38|12@1+ (0.05,-50) [-50|50] "m/sec"  E115DCU
 SG_ ObstacleAccX : 50|10@1+ (0.03,-14.97) [-14.97|14.97] "m/s^2"  E115DCU

BO_ 1172 ObstacleDataB14: 8 E115DCU
 SG_ ObstacleLength : 0|9@1+ (0.05,0) [0|25.6] "m"  E115DCU
 SG_ ObstacleWidth : 9|9@1+ (0.02,0) [0|10.24] "m"  E115DCU
 SG_ ObstacleHeight : 18|9@1+ (0.02,0) [0|10.24] "m"  E115DCU
 SG_ CIPVFlag : 27|1@1+ (1,0) [0|1] "bool"  E115DCU
 SG_ MCPFlag : 28|1@1+ (1,0) [0|1] "bool"  E115DCU
 SG_ ObstacleBlinkerInfo : 29|3@1+ (1,0) [0|4] "Enum"  E115DCU
 SG_ ObstacleBrakeLights : 32|1@1+ (1,0) [0|1] "bool"  E115DCU
 SG_ ObstacleCenterAngle : 33|16@1+ (0.01,-327.68) [-327.68|327.67] "degree"  E115DCU
 SG_ ObstaclePositionType : 49|4@1+ (1,0) [0|9] "Enum"  E115DCU
 SG_ Obstacle_TTC : 53|10@1+ (0.01,0) [0|10] "sec"  E115DCU

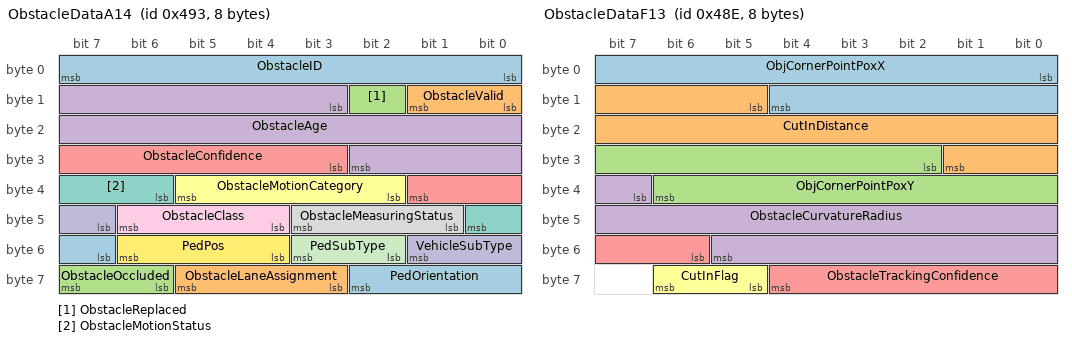
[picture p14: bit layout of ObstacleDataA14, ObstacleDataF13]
BO_ 1171 ObstacleDataA14: 8 E115DCU
 SG_ ObstacleID : 0|8@1+ (1,0) [0|255] "Counter"  E115DCU
 SG_ ObstacleValid : 8|2@1+ (1,0) [0|2] "Enum"  E115DCU
 SG_ ObstacleReplaced : 10|1@1+ (1,0) [0|1] "bool"  E115DCU
 SG_ ObstacleAge : 11|16@1+ (1,0) [0|65535] "Counter"  E115DCU
 SG_ ObstacleConfidence : 27|7@1+ (1,0) [0|100] "prob"  E115DCU
 SG_ ObstacleMotionCategory : 34|4@1+ (1,0) [0|13] "Enum"  E115DCU
 SG_ ObstacleMotionStatus : 38|3@1+ (1,0) [0|7] "Enum"  E115DCU
 SG_ ObstacleMeasuringStatus : 41|3@1+ (1,0) [0|7] "Enum"  E115DCU
 SG_ ObstacleClass : 44|3@1+ (1,0) [0|7] "Enum"  E115DCU
 SG_ VehicleSubType : 47|3@1+ (1,0) [0|7] "Enum"  E115DCU
 SG_ PedSubType : 50|2@1+ (1,0) [0|3] "Enum"  E115DCU
 SG_ PedPos : 52|3@1+ (1,0) [0|7] "Enum"  E115DCU
 SG_ PedOrientation : 55|4@1+ (1,0) [0|9] "Enum"  E115DCU
 SG_ ObstacleLaneAssignment : 59|3@1+ (1,0) [0|5] "Enum"  E115DCU
 SG_ ObstacleOccluded : 62|2@1+ (1,0) [0|3] "Enum"  E115DCU

BO_ 1166 ObstacleDataF13: 8 Vector__XXX
 SG_ ObjCornerPointPoxX : 0|13@1+ (0.0625,-250) [-250|250] "m" Vector__XXX
 SG_ CutInDistance : 13|13@1+ (0.01,-40.96) [-40.96|40.95] "m" Vector__XXX
 SG_ ObjCornerPointPoxY : 26|13@1+ (0.0625,-250) [-250|250] "m" Vector__XXX
 SG_ ObstacleCurvatureRadius : 39|15@1+ (1,-9999) [-9999|9999] "m" Vector__XXX
 SG_ ObstacleTrackingConfidence : 54|7@1+ (1,0) [0|100] "prob" Vector__XXX
 SG_ CutInFlag : 61|2@1+ (1,0) [0|2] "Enum" Vector__XXX

BO_ 1165 ObstacleDataE13: 8 E115DCU
 SG_ ObstacleAngle : 0|16@1+ (0.01,-327.68) [-327.68|327.67] "degree"  E115DCU
 SG_ ObstacleAngleStd : 16|16@1+ (0.01,0) [0|327.67] "degree"  E115DCU
 SG_ ObstacleVelXAbs : 32|12@1+ (0.05,-102.4) [-102.4|102.35] "m/sec"  E115DCU
 SG_ ObstacleVelYAbs : 44|12@1+ (0.05,-50) [-50|50] "m/sec"  E115DCU
 SG_ RollingCounter_Obstacle13 : 56|4@1+ (1,0) [0|15] "Counter"  E115DCU
 SG_ Checksum_Obstacle13 : 60|4@1+ (1,0) [0|15] "Counter"  E115DCU

BO_ 1164 ObstacleDataD13: 8 E115DCU
 SG_ ObstaclePosXSTD : 0|13@1+ (0.0625,0) [0|250] "m"  E115DCU
 SG_ ObstaclePosYSTD : 13|13@1+ (0.0625,0) [0|250] "m"  E115DCU
 SG_ ObstacleVelXSTD : 26|12@1+ (0.05,0) [0|102.35] "m/sec"  E115DCU
 SG_ ObstacleVelYSTD : 38|12@1+ (0.05,0) [0|50] "m/sec"  E115DCU
 SG_ ObstacleAccY : 50|10@1+ (0.03,-14.97) [-14.97|14.97] "m/s^2"  E115DCU

BO_ 1163 ObstacleDataC13: 8 E115DCU
 SG_ ObstaclePosX : 0|13@1+ (0.0625,-250) [-250|250] "m"  E115DCU
 SG_ ObstaclePosY : 13|13@1+ (0.0625,-250) [-250|250] "m"  E115DCU
 SG_ ObstacleVelX : 26|12@1+ (0.05,-102.4) [-102.4|102.35] "m/sec"  E115DCU
 SG_ ObstacleVelY : 38|12@1+ (0.05,-50) [-50|50] "m/sec"  E115DCU
 SG_ ObstacleAccX : 50|10@1+ (0.03,-14.97) [-14.97|14.97] "m/s^2"  E115DCU

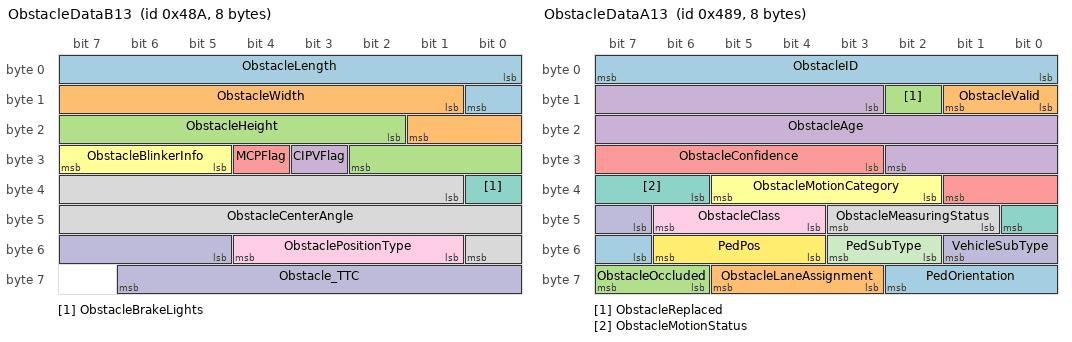
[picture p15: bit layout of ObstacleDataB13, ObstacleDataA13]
BO_ 1162 ObstacleDataB13: 8 E115DCU
 SG_ ObstacleLength : 0|9@1+ (0.05,0) [0|25.6] "m"  E115DCU
 SG_ ObstacleWidth : 9|9@1+ (0.02,0) [0|10.24] "m"  E115DCU
 SG_ ObstacleHeight : 18|9@1+ (0.02,0) [0|10.24] "m"  E115DCU
 SG_ CIPVFlag : 27|1@1+ (1,0) [0|1] "bool"  E115DCU
 SG_ MCPFlag : 28|1@1+ (1,0) [0|1] "bool"  E115DCU
 SG_ ObstacleBlinkerInfo : 29|3@1+ (1,0) [0|4] "Enum"  E115DCU
 SG_ ObstacleBrakeLights : 32|1@1+ (1,0) [0|1] "bool"  E115DCU
 SG_ ObstacleCenterAngle : 33|16@1+ (0.01,-327.68) [-327.68|327.67] "degree"  E115DCU
 SG_ ObstaclePositionType : 49|4@1+ (1,0) [0|9] "Enum"  E115DCU
 SG_ Obstacle_TTC : 53|10@1+ (0.01,0) [0|10] "sec"  E115DCU

BO_ 1161 ObstacleDataA13: 8 E115DCU
 SG_ ObstacleID : 0|8@1+ (1,0) [0|255] "Counter"  E115DCU
 SG_ ObstacleValid : 8|2@1+ (1,0) [0|2] "Enum"  E115DCU
 SG_ ObstacleReplaced : 10|1@1+ (1,0) [0|1] "bool"  E115DCU
 SG_ ObstacleAge : 11|16@1+ (1,0) [0|65535] "Counter"  E115DCU
 SG_ ObstacleConfidence : 27|7@1+ (1,0) [0|100] "prob"  E115DCU
 SG_ ObstacleMotionCategory : 34|4@1+ (1,0) [0|13] "Enum"  E115DCU
 SG_ ObstacleMotionStatus : 38|3@1+ (1,0) [0|7] "Enum"  E115DCU
 SG_ ObstacleMeasuringStatus : 41|3@1+ (1,0) [0|7] "Enum"  E115DCU
 SG_ ObstacleClass : 44|3@1+ (1,0) [0|7] "Enum"  E115DCU
 SG_ VehicleSubType : 47|3@1+ (1,0) [0|7] "Enum"  E115DCU
 SG_ PedSubType : 50|2@1+ (1,0) [0|3] "Enum"  E115DCU
 SG_ PedPos : 52|3@1+ (1,0) [0|7] "Enum"  E115DCU
 SG_ PedOrientation : 55|4@1+ (1,0) [0|9] "Enum"  E115DCU
 SG_ ObstacleLaneAssignment : 59|3@1+ (1,0) [0|5] "Enum"  E115DCU
 SG_ ObstacleOccluded : 62|2@1+ (1,0) [0|3] "Enum"  E115DCU

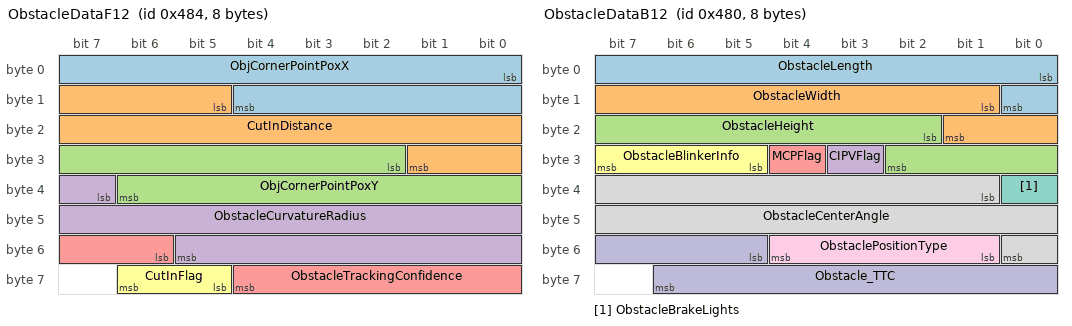
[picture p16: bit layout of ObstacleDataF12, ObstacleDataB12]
BO_ 1156 ObstacleDataF12: 8 Vector__XXX
 SG_ ObjCornerPointPoxX : 0|13@1+ (0.0625,-250) [-250|250] "m" Vector__XXX
 SG_ CutInDistance : 13|13@1+ (0.01,-40.96) [-40.96|40.95] "m" Vector__XXX
 SG_ ObjCornerPointPoxY : 26|13@1+ (0.0625,-250) [-250|250] "m" Vector__XXX
 SG_ ObstacleCurvatureRadius : 39|15@1+ (1,-9999) [-9999|9999] "m" Vector__XXX
 SG_ ObstacleTrackingConfidence : 54|7@1+ (1,0) [0|100] "prob" Vector__XXX
 SG_ CutInFlag : 61|2@1+ (1,0) [0|2] "Enum" Vector__XXX

BO_ 1155 ObstacleDataE12: 8 E115DCU
 SG_ ObstacleAngle : 0|16@1+ (0.01,-327.68) [-327.68|327.67] "degree"  E115DCU
 SG_ ObstacleAngleStd : 16|16@1+ (0.01,0) [0|327.67] "degree"  E115DCU
 SG_ ObstacleVelXAbs : 32|12@1+ (0.05,-102.4) [-102.4|102.35] "m/sec"  E115DCU
 SG_ ObstacleVelYAbs : 44|12@1+ (0.05,-50) [-50|50] "m/sec"  E115DCU
 SG_ RollingCounter_Obstacle12 : 56|4@1+ (1,0) [0|15] "Counter"  E115DCU
 SG_ Checksum_Obstacle12 : 60|4@1+ (1,0) [0|15] "Counter"  E115DCU

BO_ 1154 ObstacleDataD12: 8 E115DCU
 SG_ ObstaclePosXSTD : 0|13@1+ (0.0625,0) [0|250] "m"  E115DCU
 SG_ ObstaclePosYSTD : 13|13@1+ (0.0625,0) [0|250] "m"  E115DCU
 SG_ ObstacleVelXSTD : 26|12@1+ (0.05,0) [0|102.35] "m/sec"  E115DCU
 SG_ ObstacleVelYSTD : 38|12@1+ (0.05,0) [0|50] "m/sec"  E115DCU
 SG_ ObstacleAccY : 50|10@1+ (0.03,-14.97) [-14.97|14.97] "m/s^2"  E115DCU

BO_ 1153 ObstacleDataC12: 8 E115DCU
 SG_ ObstaclePosX : 0|13@1+ (0.0625,-250) [-250|250] "m"  E115DCU
 SG_ ObstaclePosY : 13|13@1+ (0.0625,-250) [-250|250] "m"  E115DCU
 SG_ ObstacleVelX : 26|12@1+ (0.05,-102.4) [-102.4|102.35] "m/sec"  E115DCU
 SG_ ObstacleVelY : 38|12@1+ (0.05,-50) [-50|50] "m/sec"  E115DCU
 SG_ ObstacleAccX : 50|10@1+ (0.03,-14.97) [-14.97|14.97] "m/s^2"  E115DCU

BO_ 1152 ObstacleDataB12: 8 E115DCU
 SG_ ObstacleLength : 0|9@1+ (0.05,0) [0|25.6] "m"  E115DCU
 SG_ ObstacleWidth : 9|9@1+ (0.02,0) [0|10.24] "m"  E115DCU
 SG_ ObstacleHeight : 18|9@1+ (0.02,0) [0|10.24] "m"  E115DCU
 SG_ CIPVFlag : 27|1@1+ (1,0) [0|1] "bool"  E115DCU
 SG_ MCPFlag : 28|1@1+ (1,0) [0|1] "bool"  E115DCU
 SG_ ObstacleBlinkerInfo : 29|3@1+ (1,0) [0|4] "Enum"  E115DCU
 SG_ ObstacleBrakeLights : 32|1@1+ (1,0) [0|1] "bool"  E115DCU
 SG_ ObstacleCenterAngle : 33|16@1+ (0.01,-327.68) [-327.68|327.67] "degree"  E115DCU
 SG_ ObstaclePositionType : 49|4@1+ (1,0) [0|9] "Enum"  E115DCU
 SG_ Obstacle_TTC : 53|10@1+ (0.01,0) [0|10] "sec"  E115DCU

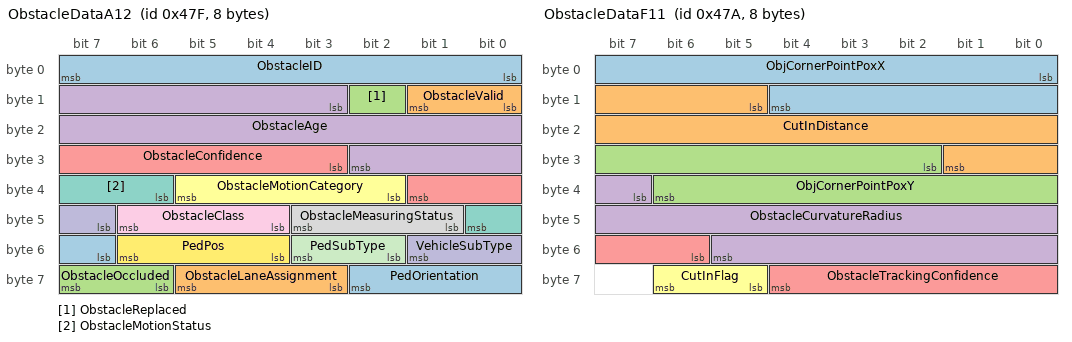
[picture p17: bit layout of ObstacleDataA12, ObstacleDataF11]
BO_ 1151 ObstacleDataA12: 8 E115DCU
 SG_ ObstacleID : 0|8@1+ (1,0) [0|255] "Counter"  E115DCU
 SG_ ObstacleValid : 8|2@1+ (1,0) [0|2] "Enum"  E115DCU
 SG_ ObstacleReplaced : 10|1@1+ (1,0) [0|1] "bool"  E115DCU
 SG_ ObstacleAge : 11|16@1+ (1,0) [0|65535] "Counter"  E115DCU
 SG_ ObstacleConfidence : 27|7@1+ (1,0) [0|100] "prob"  E115DCU
 SG_ ObstacleMotionCategory : 34|4@1+ (1,0) [0|13] "Enum"  E115DCU
 SG_ ObstacleMotionStatus : 38|3@1+ (1,0) [0|7] "Enum"  E115DCU
 SG_ ObstacleMeasuringStatus : 41|3@1+ (1,0) [0|7] "Enum"  E115DCU
 SG_ ObstacleClass : 44|3@1+ (1,0) [0|7] "Enum"  E115DCU
 SG_ VehicleSubType : 47|3@1+ (1,0) [0|7] "Enum"  E115DCU
 SG_ PedSubType : 50|2@1+ (1,0) [0|3] "Enum"  E115DCU
 SG_ PedPos : 52|3@1+ (1,0) [0|7] "Enum"  E115DCU
 SG_ PedOrientation : 55|4@1+ (1,0) [0|9] "Enum"  E115DCU
 SG_ ObstacleLaneAssignment : 59|3@1+ (1,0) [0|5] "Enum"  E115DCU
 SG_ ObstacleOccluded : 62|2@1+ (1,0) [0|3] "Enum"  E115DCU

BO_ 1146 ObstacleDataF11: 8 Vector__XXX
 SG_ ObjCornerPointPoxX : 0|13@1+ (0.0625,-250) [-250|250] "m" Vector__XXX
 SG_ CutInDistance : 13|13@1+ (0.01,-40.96) [-40.96|40.95] "m" Vector__XXX
 SG_ ObjCornerPointPoxY : 26|13@1+ (0.0625,-250) [-250|250] "m" Vector__XXX
 SG_ ObstacleCurvatureRadius : 39|15@1+ (1,-9999) [-9999|9999] "m" Vector__XXX
 SG_ ObstacleTrackingConfidence : 54|7@1+ (1,0) [0|100] "prob" Vector__XXX
 SG_ CutInFlag : 61|2@1+ (1,0) [0|2] "Enum" Vector__XXX

BO_ 1145 ObstacleDataE11: 8 E115DCU
 SG_ ObstacleAngle : 0|16@1+ (0.01,-327.68) [-327.68|327.67] "degree"  E115DCU
 SG_ ObstacleAngleStd : 16|16@1+ (0.01,0) [0|327.67] "degree"  E115DCU
 SG_ ObstacleVelXAbs : 32|12@1+ (0.05,-102.4) [-102.4|102.35] "m/sec"  E115DCU
 SG_ ObstacleVelYAbs : 44|12@1+ (0.05,-50) [-50|50] "m/sec"  E115DCU
 SG_ RollingCounter_Obstacle11 : 56|4@1+ (1,0) [0|15] "Counter"  E115DCU
 SG_ Checksum_Obstacle11 : 60|4@1+ (1,0) [0|15] "Counter"  E115DCU

BO_ 1144 ObstacleDataD11: 8 E115DCU
 SG_ ObstaclePosXSTD : 0|13@1+ (0.0625,0) [0|250] "m"  E115DCU
 SG_ ObstaclePosYSTD : 13|13@1+ (0.0625,0) [0|250] "m"  E115DCU
 SG_ ObstacleVelXSTD : 26|12@1+ (0.05,0) [0|102.35] "m/sec"  E115DCU
 SG_ ObstacleVelYSTD : 38|12@1+ (0.05,0) [0|50] "m/sec"  E115DCU
 SG_ ObstacleAccY : 50|10@1+ (0.03,-14.97) [-14.97|14.97] "m/s^2"  E115DCU

BO_ 1143 ObstacleDataC11: 8 E115DCU
 SG_ ObstaclePosX : 0|13@1+ (0.0625,-250) [-250|250] "m"  E115DCU
 SG_ ObstaclePosY : 13|13@1+ (0.0625,-250) [-250|250] "m"  E115DCU
 SG_ ObstacleVelX : 26|12@1+ (0.05,-102.4) [-102.4|102.35] "m/sec"  E115DCU
 SG_ ObstacleVelY : 38|12@1+ (0.05,-50) [-50|50] "m/sec"  E115DCU
 SG_ ObstacleAccX : 50|10@1+ (0.03,-14.97) [-14.97|14.97] "m/s^2"  E115DCU

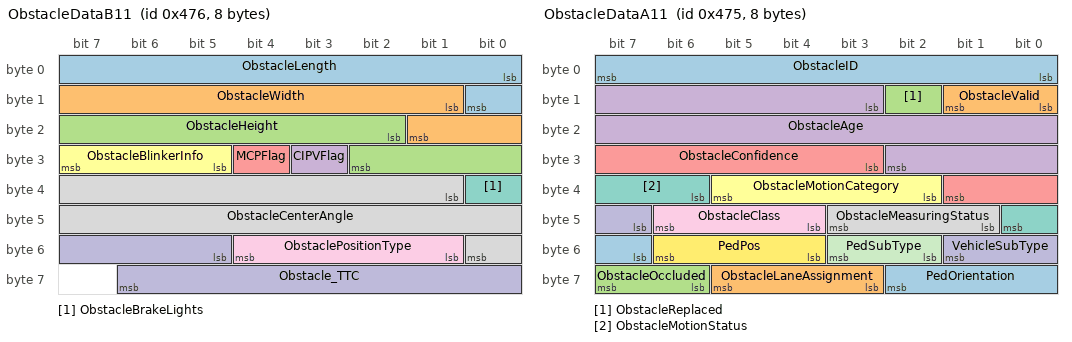
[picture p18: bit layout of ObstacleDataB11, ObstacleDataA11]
BO_ 1142 ObstacleDataB11: 8 E115DCU
 SG_ ObstacleLength : 0|9@1+ (0.05,0) [0|25.6] "m"  E115DCU
 SG_ ObstacleWidth : 9|9@1+ (0.02,0) [0|10.24] "m"  E115DCU
 SG_ ObstacleHeight : 18|9@1+ (0.02,0) [0|10.24] "m"  E115DCU
 SG_ CIPVFlag : 27|1@1+ (1,0) [0|1] "bool"  E115DCU
 SG_ MCPFlag : 28|1@1+ (1,0) [0|1] "bool"  E115DCU
 SG_ ObstacleBlinkerInfo : 29|3@1+ (1,0) [0|4] "Enum"  E115DCU
 SG_ ObstacleBrakeLights : 32|1@1+ (1,0) [0|1] "bool"  E115DCU
 SG_ ObstacleCenterAngle : 33|16@1+ (0.01,-327.68) [-327.68|327.67] "degree"  E115DCU
 SG_ ObstaclePositionType : 49|4@1+ (1,0) [0|9] "Enum"  E115DCU
 SG_ Obstacle_TTC : 53|10@1+ (0.01,0) [0|10] "sec"  E115DCU

BO_ 1141 ObstacleDataA11: 8 E115DCU
 SG_ ObstacleID : 0|8@1+ (1,0) [0|255] "Counter"  E115DCU
 SG_ ObstacleValid : 8|2@1+ (1,0) [0|2] "Enum"  E115DCU
 SG_ ObstacleReplaced : 10|1@1+ (1,0) [0|1] "bool"  E115DCU
 SG_ ObstacleAge : 11|16@1+ (1,0) [0|65535] "Counter"  E115DCU
 SG_ ObstacleConfidence : 27|7@1+ (1,0) [0|100] "prob"  E115DCU
 SG_ ObstacleMotionCategory : 34|4@1+ (1,0) [0|13] "Enum"  E115DCU
 SG_ ObstacleMotionStatus : 38|3@1+ (1,0) [0|7] "Enum"  E115DCU
 SG_ ObstacleMeasuringStatus : 41|3@1+ (1,0) [0|7] "Enum"  E115DCU
 SG_ ObstacleClass : 44|3@1+ (1,0) [0|7] "Enum"  E115DCU
 SG_ VehicleSubType : 47|3@1+ (1,0) [0|7] "Enum"  E115DCU
 SG_ PedSubType : 50|2@1+ (1,0) [0|3] "Enum"  E115DCU
 SG_ PedPos : 52|3@1+ (1,0) [0|7] "Enum"  E115DCU
 SG_ PedOrientation : 55|4@1+ (1,0) [0|9] "Enum"  E115DCU
 SG_ ObstacleLaneAssignment : 59|3@1+ (1,0) [0|5] "Enum"  E115DCU
 SG_ ObstacleOccluded : 62|2@1+ (1,0) [0|3] "Enum"  E115DCU

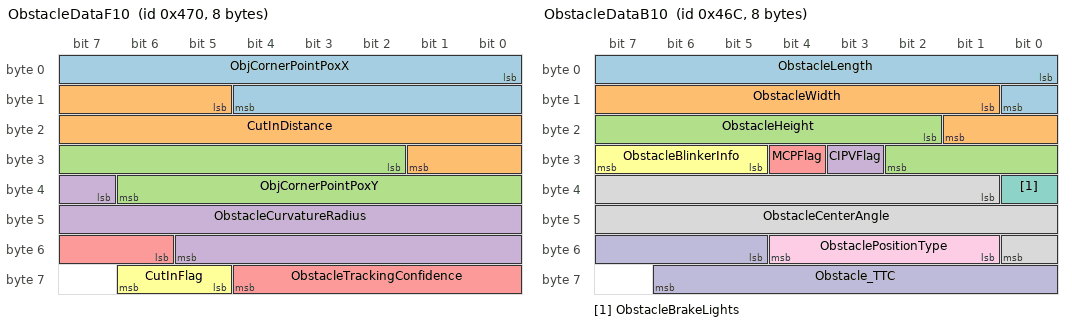
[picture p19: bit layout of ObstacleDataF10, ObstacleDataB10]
BO_ 1136 ObstacleDataF10: 8 Vector__XXX
 SG_ ObjCornerPointPoxX : 0|13@1+ (0.0625,-250) [-250|250] "m" Vector__XXX
 SG_ CutInDistance : 13|13@1+ (0.01,-40.96) [-40.96|40.95] "m" Vector__XXX
 SG_ ObjCornerPointPoxY : 26|13@1+ (0.0625,-250) [-250|250] "m" Vector__XXX
 SG_ ObstacleCurvatureRadius : 39|15@1+ (1,-9999) [-9999|9999] "m" Vector__XXX
 SG_ ObstacleTrackingConfidence : 54|7@1+ (1,0) [0|100] "prob" Vector__XXX
 SG_ CutInFlag : 61|2@1+ (1,0) [0|2] "Enum" Vector__XXX

BO_ 1135 ObstacleDataE10: 8 E115DCU
 SG_ ObstacleAngle : 0|16@1+ (0.01,-327.68) [-327.68|327.67] "degree"  E115DCU
 SG_ ObstacleAngleStd : 16|16@1+ (0.01,0) [0|327.67] "degree"  E115DCU
 SG_ ObstacleVelXAbs : 32|12@1+ (0.05,-102.4) [-102.4|102.35] "m/sec"  E115DCU
 SG_ ObstacleVelYAbs : 44|12@1+ (0.05,-50) [-50|50] "m/sec"  E115DCU
 SG_ RollingCounter_Obstacle10 : 56|4@1+ (1,0) [0|15] "Counter"  E115DCU
 SG_ Checksum_Obstacle10 : 60|4@1+ (1,0) [0|15] "Counter"  E115DCU

BO_ 1134 ObstacleDataD10: 8 E115DCU
 SG_ ObstaclePosXSTD : 0|13@1+ (0.0625,0) [0|250] "m"  E115DCU
 SG_ ObstaclePosYSTD : 13|13@1+ (0.0625,0) [0|250] "m"  E115DCU
 SG_ ObstacleVelXSTD : 26|12@1+ (0.05,0) [0|102.35] "m/sec"  E115DCU
 SG_ ObstacleVelYSTD : 38|12@1+ (0.05,0) [0|50] "m/sec"  E115DCU
 SG_ ObstacleAccY : 50|10@1+ (0.03,-14.97) [-14.97|14.97] "m/s^2"  E115DCU

BO_ 1133 ObstacleDataC10: 8 E115DCU
 SG_ ObstaclePosX : 0|13@1+ (0.0625,-250) [-250|250] "m"  E115DCU
 SG_ ObstaclePosY : 13|13@1+ (0.0625,-250) [-250|250] "m"  E115DCU
 SG_ ObstacleVelX : 26|12@1+ (0.05,-102.4) [-102.4|102.35] "m/sec"  E115DCU
 SG_ ObstacleVelY : 38|12@1+ (0.05,-50) [-50|50] "m/sec"  E115DCU
 SG_ ObstacleAccX : 50|10@1+ (0.03,-14.97) [-14.97|14.97] "m/s^2"  E115DCU

BO_ 1132 ObstacleDataB10: 8 E115DCU
 SG_ ObstacleLength : 0|9@1+ (0.05,0) [0|25.6] "m"  E115DCU
 SG_ ObstacleWidth : 9|9@1+ (0.02,0) [0|10.24] "m"  E115DCU
 SG_ ObstacleHeight : 18|9@1+ (0.02,0) [0|10.24] "m"  E115DCU
 SG_ CIPVFlag : 27|1@1+ (1,0) [0|1] "bool"  E115DCU
 SG_ MCPFlag : 28|1@1+ (1,0) [0|1] "bool"  E115DCU
 SG_ ObstacleBlinkerInfo : 29|3@1+ (1,0) [0|4] "Enum"  E115DCU
 SG_ ObstacleBrakeLights : 32|1@1+ (1,0) [0|1] "bool"  E115DCU
 SG_ ObstacleCenterAngle : 33|16@1+ (0.01,-327.68) [-327.68|327.67] "degree"  E115DCU
 SG_ ObstaclePositionType : 49|4@1+ (1,0) [0|9] "Enum"  E115DCU
 SG_ Obstacle_TTC : 53|10@1+ (0.01,0) [0|10] "sec"  E115DCU

CM_ SG_ 1040 NumObstacles "Total number of obstacles in this frame";
CM_ SG_ 1040 ID_CIPV "ObstacleID of CIPV target, linked 'CIPVFlag'";
CM_ SG_ 1040 ID_MCP "ObstacleID of MCP target, linked 'MCPFlag'";
CM_ SG_ 1040 CIPV_TTC "eTTC value for CIPV(just for vehicle and cyclist), calculated from target perception distance, velocity and acceleration/deceleration, by the method of enhanced TTC. ";
CM_ SG_ 1040 CIPV_TTC_Valid "If the TTC Value is valid. Valid means within range[0,10]; Invalid means no value or TTC minus zero.";
CM_ SG_ 1040 MCP_TTC "eTTC value for MCP(just for pedestrian), calculated from target perception distance, velocity and acceleration/deceleration, by the method of enhanced TTC. ";
CM_ SG_ 1040 MCP_TTC_Valid "If the TTC Value is valid. Valid means within range[0,10]; Invalid means no value or TTC minus zero.";
CM_ SG_ 1040 ProtocolMajorVersion "Major Version of Protocol";
CM_ SG_ 1040 ProtocolMinorVersion "Minor Version of Protocol";
CM_ SG_ 1040 CIPV_HWM_Valid "If the HWM Value is valid. Valid means within range[0,10]; Invalid means no value or HWM minus zero.";
CM_ SG_ 1040 CIPV_HWM "HWM value for CIPV, calculated from target perception distance devided by host speed. ";
CM_ SG_ 1236 ObjCornerPointPoxX "The longitudinal distance of the obstacle's nearest coner to host vehicle in VCS. Most situation the corner point is the potential cut-in frontal corner point. Not valid for cyclist and pedestrian";
CM_ SG_ 1236 CutInDistance "The lateral relative distance of the obstacle's nearest coner to host lane line center. Positive means the vehicle now out of host lane, negative means the vehicle had been part in host lane. Not valid for cyclist and pedestrian";
CM_ SG_ 1236 ObjCornerPointPoxY "The lateral distance of the obstacle's nearest coner to host vehicle in VCS. Most situation the corner point is the potential cut-in frontal corner point. Not valid for cyclist and pedestrian";
CM_ SG_ 1236 ObstacleCurvatureRadius "Curvature radius of obstacle, the tendency of turning, calculated by single frame, mainly used when fusion with Radar";
CM_ SG_ 1236 ObstacleTrackingConfidence "Obstacle Tracking Confidence, which judged the confidence of tracking status.";
CM_ SG_ 1236 CutInFlag "Cut-in status for obstacle. Normal target output as 0; when made cut-in-hostlane action continuously output as 1; when target appeared from edge of FOV and target only partially visible output as 2. Not valid for cyclist and pedestrian";
CM_ SG_ 1235 ObstacleAngle "The heading angle of vehicle or cyclist, not valid pedestrian";
CM_ SG_ 1235 ObstacleAngleStd "The standard deviation of heading angle of obstacle, calculated from Tracking Filter";
CM_ SG_ 1235 ObstacleVelXAbs "The abusolute longitude velocity of the obstacle. ";
CM_ SG_ 1235 ObstacleVelYAbs "The abusolute lateral velocity of the obstacle. ";
CM_ SG_ 1235 RollingCounter_Obstacle20 "Rolling Counter of the msg ObstacleDataA20~ObstacleDataF20, Rolling between 0 and 15 SPI frame by SPI frame";
CM_ SG_ 1235 Checksum_Obstacle20 "CRC Checksum of the msg ObstacleDataA20~ObstacleDataF20, all the signals except Checksum_Obstacle_Signal are included. CRC4 algorithm.";
CM_ SG_ 1234 ObstaclePosXSTD "the standard deviation of longitudinal distance (ObstaclePosX) to observation point of obstacle in VCS, calculated from Tracking Filter";
CM_ SG_ 1234 ObstaclePosYSTD "the standard deviation of lateral distance (ObstaclePosY) to observation point of obstacle in VCS, calculated from Tracking Filter  ";
CM_ SG_ 1234 ObstacleVelXSTD "the standard deviation of longitude velocity (ObstacleVelX) of the obstacle, calculated from Tracking Filter  ";
CM_ SG_ 1234 ObstacleVelYSTD "the standard deviation of  lateral velocity (ObstacleVelY) of the obstacle, calculated from Tracking Filter  ";
CM_ SG_ 1234 ObstacleAccY "The lateral absolute acceleration of the object.";
CM_ SG_ 1233 ObstaclePosX "The longitudinal distance to observation point of obstacle in VCS";
CM_ SG_ 1233 ObstaclePosY "The lateral distance to observation point of obstacle in VCS, left positive, right negative";
CM_ SG_ 1233 ObstacleVelX "The relative longitude velocity of the obstacle and host vehicle";
CM_ SG_ 1233 ObstacleVelY "The relative lateral velocity of the obstacle and host vehicle, left positive, right negative";
CM_ SG_ 1233 ObstacleAccX "The longitude absolute acceleration of the object.";
CM_ SG_ 1232 ObstacleLength "Length of obstacle, valid for vehicle and cyclist. For pedestrian output as 0.";
CM_ SG_ 1232 ObstacleWidth "Width of obstacle rear, valid for vehicle and cyclist. For pedestrian output as 0.";
CM_ SG_ 1232 ObstacleHeight "Height of obstacle, valid for vehicle, cyclist and pedestrian";
CM_ SG_ 1232 CIPVFlag "If this obstacle CIPV, closest target(vehicle and cyclist) in path. Calculated by fusion of host lane path and predicted path";
CM_ SG_ 1232 MCPFlag "If this obstacle MCP, most critical target(pedestrian). Calculated by fusion of host lane path and predicted path";
CM_ SG_ 1232 ObstacleBlinkerInfo "Turn light signal in single frame, just valid for vehicle target. ";
CM_ SG_ 1232 ObstacleBrakeLights "Brake light signal in single frame, just valid for vehicle target";
CM_ SG_ 1232 ObstacleCenterAngle "The Angle Between the orientation of Host Vehicle and the orientation from the front center of Host Vehicle  to the Reference Point of the target. Mainly used when fusion with front Radar";
CM_ SG_ 1232 ObstaclePositionType "Observation point type of the obstacle, mainly depending on the heading angle of the obstacle. For preceding or oncoming target, output as 2; for crossing or turning target, output as 7 or 8. Just valid for vehicle target";
CM_ SG_ 1232 Obstacle_TTC "eTTC value for this obstacle, calculated from target perception distance, velocity and deceleration, by the method of enhanced TTC";
CM_ SG_ 1231 ObstacleID "Object ID, valid value is 1 to 255, 0 as default. 1 to 200 for vehicle, 201 to 255 for pedestrian";
CM_ SG_ 1231 ObstacleValid "Obstacle Valid info, when target exists, 'ObstacleValid'=1 in first frame, 'ObstacleValid'=2 from second frame";
CM_ SG_ 1231 ObstacleReplaced "Reserved";
CM_ SG_ 1231 ObstacleAge "Frame age of this obstacle exists, because some post-process logic to ensure the tracking status and confidence, in the first frame maybe not be '1'";
CM_ SG_ 1231 ObstacleConfidence "Existence probability of Obstacle, calculated from CNN detection, when > 6 continuously means high conf obstacle target. ";
CM_ SG_ 1231 ObstacleMotionCategory "The signal is based on our estimation of where the target is now relatively to the lanes, its rate of change, and our estimation of where it is going to be within one second. Just valid when 'ObstacleClass'=1, vehicle target";
CM_ SG_ 1231 ObstacleMotionStatus "The target is moving or stopped. Just valid when 'ObstacleClass'=1, vehicle target";
CM_ SG_ 1231 ObstacleMeasuringStatus "Were measurements predicted, old, or not valid, 'PREDICTED' will be continuously less than 3 frames";
CM_ SG_ 1231 ObstacleClass "Classification of this object";
CM_ SG_ 1231 VehicleSubType "Vehicle Sub type, when 'ObstacleClass'=1";
CM_ SG_ 1231 PedSubType "Pedestrian Sub type, when 'ObstacleClass'=2";
CM_ SG_ 1231 PedPos "Pedestrian posture, for normal standing person, output as 'Pedestrian'. For cyclist, no further posture could be classificated";
CM_ SG_ 1231 PedOrientation "Pedestrian orientation, classification in single frame in image space";
CM_ SG_ 1231 ObstacleLaneAssignment "Obstacle Lane Assignment £¨Which lane a vehicle belongs to£©";
CM_ SG_ 1231 ObstacleOccluded "Obstacle is occluded or not in image space. Just when the obstacle was partially occluded could output as 2";
CM_ SG_ 1226 ObjCornerPointPoxX "The longitudinal distance of the obstacle's nearest coner to host vehicle in VCS. Most situation the corner point is the potential cut-in frontal corner point. Not valid for cyclist and pedestrian";
CM_ SG_ 1226 CutInDistance "The lateral relative distance of the obstacle's nearest coner to host lane line center. Positive means the vehicle now out of host lane, negative means the vehicle had been part in host lane. Not valid for cyclist and pedestrian";
CM_ SG_ 1226 ObjCornerPointPoxY "The lateral distance of the obstacle's nearest coner to host vehicle in VCS. Most situation the corner point is the potential cut-in frontal corner point. Not valid for cyclist and pedestrian";
CM_ SG_ 1226 ObstacleCurvatureRadius "Curvature radius of obstacle, the tendency of turning, calculated by single frame, mainly used when fusion with Radar";
CM_ SG_ 1226 ObstacleTrackingConfidence "Obstacle Tracking Confidence, which judged the confidence of tracking status.";
CM_ SG_ 1226 CutInFlag "Cut-in status for obstacle. Normal target output as 0; when made cut-in-hostlane action continuously output as 1; when target appeared from edge of FOV and target only partially visible output as 2. Not valid for cyclist and pedestrian";
CM_ SG_ 1225 ObstacleAngle "The heading angle of vehicle or cyclist, not valid pedestrian";
CM_ SG_ 1225 ObstacleAngleStd "The standard deviation of heading angle of obstacle, calculated from Tracking Filter";
CM_ SG_ 1225 ObstacleVelXAbs "The abusolute longitude velocity of the obstacle. ";
CM_ SG_ 1225 ObstacleVelYAbs "The abusolute lateral velocity of the obstacle. ";
CM_ SG_ 1225 RollingCounter_Obstacle19 "Rolling Counter of the msg ObstacleDataA19~ObstacleDataF19, Rolling between 0 and 15 SPI frame by SPI frame";
CM_ SG_ 1225 Checksum_Obstacle19 "CRC Checksum of the msg ObstacleDataA19~ObstacleDataF19, all the signals except Checksum_Obstacle_Signal are included. CRC4 algorithm.";
CM_ SG_ 1224 ObstaclePosXSTD "the standard deviation of longitudinal distance (ObstaclePosX) to observation point of obstacle in VCS, calculated from Tracking Filter";
CM_ SG_ 1224 ObstaclePosYSTD "the standard deviation of lateral distance (ObstaclePosY) to observation point of obstacle in VCS, calculated from Tracking Filter  ";
CM_ SG_ 1224 ObstacleVelXSTD "the standard deviation of longitude velocity (ObstacleVelX) of the obstacle, calculated from Tracking Filter  ";
CM_ SG_ 1224 ObstacleVelYSTD "the standard deviation of  lateral velocity (ObstacleVelY) of the obstacle, calculated from Tracking Filter  ";
CM_ SG_ 1224 ObstacleAccY "The lateral absolute acceleration of the object.";
CM_ SG_ 1223 ObstaclePosX "The longitudinal distance to observation point of obstacle in VCS";
CM_ SG_ 1223 ObstaclePosY "The lateral distance to observation point of obstacle in VCS, left positive, right negative";
CM_ SG_ 1223 ObstacleVelX "The relative longitude velocity of the obstacle and host vehicle";
CM_ SG_ 1223 ObstacleVelY "The relative lateral velocity of the obstacle and host vehicle, left positive, right negative";
CM_ SG_ 1223 ObstacleAccX "The longitude absolute acceleration of the object.";
CM_ SG_ 1222 ObstacleLength "Length of obstacle, valid for vehicle and cyclist. For pedestrian output as 0.";
CM_ SG_ 1222 ObstacleWidth "Width of obstacle rear, valid for vehicle and cyclist. For pedestrian output as 0.";
CM_ SG_ 1222 ObstacleHeight "Height of obstacle, valid for vehicle, cyclist and pedestrian";
CM_ SG_ 1222 CIPVFlag "If this obstacle CIPV, closest target(vehicle and cyclist) in path. Calculated by fusion of host lane path and predicted path";
CM_ SG_ 1222 MCPFlag "If this obstacle MCP, most critical target(pedestrian). Calculated by fusion of host lane path and predicted path";
CM_ SG_ 1222 ObstacleBlinkerInfo "Turn light signal in single frame, just valid for vehicle target. ";
CM_ SG_ 1222 ObstacleBrakeLights "Brake light signal in single frame, just valid for vehicle target";
CM_ SG_ 1222 ObstacleCenterAngle "The Angle Between the orientation of Host Vehicle and the orientation from the front center of Host Vehicle  to the Reference Point of the target. Mainly used when fusion with front Radar";
CM_ SG_ 1222 ObstaclePositionType "Observation point type of the obstacle, mainly depending on the heading angle of the obstacle. For preceding or oncoming target, output as 2; for crossing or turning target, output as 7 or 8. Just valid for vehicle target";
CM_ SG_ 1222 Obstacle_TTC "eTTC value for this obstacle, calculated from target perception distance, velocity and deceleration, by the method of enhanced TTC";
CM_ SG_ 1221 ObstacleID "Object ID, valid value is 1 to 255, 0 as default. 1 to 200 for vehicle, 201 to 255 for pedestrian";
CM_ SG_ 1221 ObstacleValid "Obstacle Valid info, when target exists, 'ObstacleValid'=1 in first frame, 'ObstacleValid'=2 from second frame";
CM_ SG_ 1221 ObstacleReplaced "Reserved";
CM_ SG_ 1221 ObstacleAge "Frame age of this obstacle exists, because some post-process logic to ensure the tracking status and confidence, in the first frame maybe not be '1'";
CM_ SG_ 1221 ObstacleConfidence "Existence probability of Obstacle, calculated from CNN detection, when > 6 continuously means high conf obstacle target. ";
CM_ SG_ 1221 ObstacleMotionCategory "The signal is based on our estimation of where the target is now relatively to the lanes, its rate of change, and our estimation of where it is going to be within one second. Just valid when 'ObstacleClass'=1, vehicle target";
CM_ SG_ 1221 ObstacleMotionStatus "The target is moving or stopped. Just valid when 'ObstacleClass'=1, vehicle target";
CM_ SG_ 1221 ObstacleMeasuringStatus "Were measurements predicted, old, or not valid, 'PREDICTED' will be continuously less than 3 frames";
CM_ SG_ 1221 ObstacleClass "Classification of this object";
CM_ SG_ 1221 VehicleSubType "Vehicle Sub type, when 'ObstacleClass'=1";
CM_ SG_ 1221 PedSubType "Pedestrian Sub type, when 'ObstacleClass'=2";
CM_ SG_ 1221 PedPos "Pedestrian posture, for normal standing person, output as 'Pedestrian'. For cyclist, no further posture could be classificated";
CM_ SG_ 1221 PedOrientation "Pedestrian orientation, classification in single frame in image space";
CM_ SG_ 1221 ObstacleLaneAssignment "Obstacle Lane Assignment £¨Which lane a vehicle belongs to£©";
CM_ SG_ 1221 ObstacleOccluded "Obstacle is occluded or not in image space. Just when the obstacle was partially occluded could output as 2";
CM_ SG_ 1216 ObjCornerPointPoxX "The longitudinal distance of the obstacle's nearest coner to host vehicle in VCS. Most situation the corner point is the potential cut-in frontal corner point. Not valid for cyclist and pedestrian";
CM_ SG_ 1216 CutInDistance "The lateral relative distance of the obstacle's nearest coner to host lane line center. Positive means the vehicle now out of host lane, negative means the vehicle had been part in host lane. Not valid for cyclist and pedestrian";
CM_ SG_ 1216 ObjCornerPointPoxY "The lateral distance of the obstacle's nearest coner to host vehicle in VCS. Most situation the corner point is the potential cut-in frontal corner point. Not valid for cyclist and pedestrian";
CM_ SG_ 1216 ObstacleCurvatureRadius "Curvature radius of obstacle, the tendency of turning, calculated by single frame, mainly used when fusion with Radar";
CM_ SG_ 1216 ObstacleTrackingConfidence "Obstacle Tracking Confidence, which judged the confidence of tracking status.";
CM_ SG_ 1216 CutInFlag "Cut-in status for obstacle. Normal target output as 0; when made cut-in-hostlane action continuously output as 1; when target appeared from edge of FOV and target only partially visible output as 2. Not valid for cyclist and pedestrian";
CM_ SG_ 1215 ObstacleAngle "The heading angle of vehicle or cyclist, not valid pedestrian";
CM_ SG_ 1215 ObstacleAngleStd "The standard deviation of heading angle of obstacle, calculated from Tracking Filter";
CM_ SG_ 1215 ObstacleVelXAbs "The abusolute longitude velocity of the obstacle. ";
CM_ SG_ 1215 ObstacleVelYAbs "The abusolute lateral velocity of the obstacle. ";
CM_ SG_ 1215 RollingCounter_Obstacle18 "Rolling Counter of the msg ObstacleDataA18~ObstacleDataF18, Rolling between 0 and 15 SPI frame by SPI frame";
CM_ SG_ 1215 Checksum_Obstacle18 "CRC Checksum of the msg ObstacleDataA18~ObstacleDataF18, all the signals except Checksum_Obstacle_Signal are included. CRC4 algorithm.";
CM_ SG_ 1214 ObstaclePosXSTD "the standard deviation of longitudinal distance (ObstaclePosX) to observation point of obstacle in VCS, calculated from Tracking Filter";
CM_ SG_ 1214 ObstaclePosYSTD "the standard deviation of lateral distance (ObstaclePosY) to observation point of obstacle in VCS, calculated from Tracking Filter  ";
CM_ SG_ 1214 ObstacleVelXSTD "the standard deviation of longitude velocity (ObstacleVelX) of the obstacle, calculated from Tracking Filter  ";
CM_ SG_ 1214 ObstacleVelYSTD "the standard deviation of  lateral velocity (ObstacleVelY) of the obstacle, calculated from Tracking Filter  ";
CM_ SG_ 1214 ObstacleAccY "The lateral absolute acceleration of the object.";
CM_ SG_ 1213 ObstaclePosX "The longitudinal distance to observation point of obstacle in VCS";
CM_ SG_ 1213 ObstaclePosY "The lateral distance to observation point of obstacle in VCS, left positive, right negative";
CM_ SG_ 1213 ObstacleVelX "The relative longitude velocity of the obstacle and host vehicle";
CM_ SG_ 1213 ObstacleVelY "The relative lateral velocity of the obstacle and host vehicle, left positive, right negative";
CM_ SG_ 1213 ObstacleAccX "The longitude absolute acceleration of the object.";
CM_ SG_ 1212 ObstacleLength "Length of obstacle, valid for vehicle and cyclist. For pedestrian output as 0.";
CM_ SG_ 1212 ObstacleWidth "Width of obstacle rear, valid for vehicle and cyclist. For pedestrian output as 0.";
CM_ SG_ 1212 ObstacleHeight "Height of obstacle, valid for vehicle, cyclist and pedestrian";
CM_ SG_ 1212 CIPVFlag "If this obstacle CIPV, closest target(vehicle and cyclist) in path. Calculated by fusion of host lane path and predicted path";
CM_ SG_ 1212 MCPFlag "If this obstacle MCP, most critical target(pedestrian). Calculated by fusion of host lane path and predicted path";
CM_ SG_ 1212 ObstacleBlinkerInfo "Turn light signal in single frame, just valid for vehicle target. ";
CM_ SG_ 1212 ObstacleBrakeLights "Brake light signal in single frame, just valid for vehicle target";
CM_ SG_ 1212 ObstacleCenterAngle "The Angle Between the orientation of Host Vehicle and the orientation from the front center of Host Vehicle  to the Reference Point of the target. Mainly used when fusion with front Radar";
CM_ SG_ 1212 ObstaclePositionType "Observation point type of the obstacle, mainly depending on the heading angle of the obstacle. For preceding or oncoming target, output as 2; for crossing or turning target, output as 7 or 8. Just valid for vehicle target";
CM_ SG_ 1212 Obstacle_TTC "eTTC value for this obstacle, calculated from target perception distance, velocity and deceleration, by the method of enhanced TTC";
CM_ SG_ 1211 ObstacleID "Object ID, valid value is 1 to 255, 0 as default. 1 to 200 for vehicle, 201 to 255 for pedestrian";
CM_ SG_ 1211 ObstacleValid "Obstacle Valid info, when target exists, 'ObstacleValid'=1 in first frame, 'ObstacleValid'=2 from second frame";
CM_ SG_ 1211 ObstacleReplaced "Reserved";
CM_ SG_ 1211 ObstacleAge "Frame age of this obstacle exists, because some post-process logic to ensure the tracking status and confidence, in the first frame maybe not be '1'";
CM_ SG_ 1211 ObstacleConfidence "Existence probability of Obstacle, calculated from CNN detection, when > 6 continuously means high conf obstacle target. ";
CM_ SG_ 1211 ObstacleMotionCategory "The signal is based on our estimation of where the target is now relatively to the lanes, its rate of change, and our estimation of where it is going to be within one second. Just valid when 'ObstacleClass'=1, vehicle target";
CM_ SG_ 1211 ObstacleMotionStatus "The target is moving or stopped. Just valid when 'ObstacleClass'=1, vehicle target";
CM_ SG_ 1211 ObstacleMeasuringStatus "Were measurements predicted, old, or not valid, 'PREDICTED' will be continuously less than 3 frames";
CM_ SG_ 1211 ObstacleClass "Classification of this object";
CM_ SG_ 1211 VehicleSubType "Vehicle Sub type, when 'ObstacleClass'=1";
CM_ SG_ 1211 PedSubType "Pedestrian Sub type, when 'ObstacleClass'=2";
CM_ SG_ 1211 PedPos "Pedestrian posture, for normal standing person, output as 'Pedestrian'. For cyclist, no further posture could be classificated";
CM_ SG_ 1211 PedOrientation "Pedestrian orientation, classification in single frame in image space";
CM_ SG_ 1211 ObstacleLaneAssignment "Obstacle Lane Assignment £¨Which lane a vehicle belongs to£©";
CM_ SG_ 1211 ObstacleOccluded "Obstacle is occluded or not in image space. Just when the obstacle was partially occluded could output as 2";
CM_ SG_ 1206 ObjCornerPointPoxX "The longitudinal distance of the obstacle's nearest coner to host vehicle in VCS. Most situation the corner point is the potential cut-in frontal corner point. Not valid for cyclist and pedestrian";
CM_ SG_ 1206 CutInDistance "The lateral relative distance of the obstacle's nearest coner to host lane line center. Positive means the vehicle now out of host lane, negative means the vehicle had been part in host lane. Not valid for cyclist and pedestrian";
CM_ SG_ 1206 ObjCornerPointPoxY "The lateral distance of the obstacle's nearest coner to host vehicle in VCS. Most situation the corner point is the potential cut-in frontal corner point. Not valid for cyclist and pedestrian";
CM_ SG_ 1206 ObstacleCurvatureRadius "Curvature radius of obstacle, the tendency of turning, calculated by single frame, mainly used when fusion with Radar";
CM_ SG_ 1206 ObstacleTrackingConfidence "Obstacle Tracking Confidence, which judged the confidence of tracking status.";
CM_ SG_ 1206 CutInFlag "Cut-in status for obstacle. Normal target output as 0; when made cut-in-hostlane action continuously output as 1; when target appeared from edge of FOV and target only partially visible output as 2. Not valid for cyclist and pedestrian";
CM_ SG_ 1205 ObstacleAngle "The heading angle of vehicle or cyclist, not valid pedestrian";
CM_ SG_ 1205 ObstacleAngleStd "The standard deviation of heading angle of obstacle, calculated from Tracking Filter";
CM_ SG_ 1205 ObstacleVelXAbs "The abusolute longitude velocity of the obstacle. ";
CM_ SG_ 1205 ObstacleVelYAbs "The abusolute lateral velocity of the obstacle. ";
CM_ SG_ 1205 RollingCounter_Obstacle17 "Rolling Counter of the msg ObstacleDataA17~ObstacleDataF17, Rolling between 0 and 15 SPI frame by SPI frame";
CM_ SG_ 1205 Checksum_Obstacle17 "CRC Checksum of the msg ObstacleDataA17~ObstacleDataF17, all the signals except Checksum_Obstacle_Signal are included. CRC4 algorithm.";
CM_ SG_ 1204 ObstaclePosXSTD "the standard deviation of longitudinal distance (ObstaclePosX) to observation point of obstacle in VCS, calculated from Tracking Filter";
CM_ SG_ 1204 ObstaclePosYSTD "the standard deviation of lateral distance (ObstaclePosY) to observation point of obstacle in VCS, calculated from Tracking Filter  ";
CM_ SG_ 1204 ObstacleVelXSTD "the standard deviation of longitude velocity (ObstacleVelX) of the obstacle, calculated from Tracking Filter  ";
CM_ SG_ 1204 ObstacleVelYSTD "the standard deviation of  lateral velocity (ObstacleVelY) of the obstacle, calculated from Tracking Filter  ";
CM_ SG_ 1204 ObstacleAccY "The lateral absolute acceleration of the object.";
CM_ SG_ 1203 ObstaclePosX "The longitudinal distance to observation point of obstacle in VCS";
CM_ SG_ 1203 ObstaclePosY "The lateral distance to observation point of obstacle in VCS, left positive, right negative";
CM_ SG_ 1203 ObstacleVelX "The relative longitude velocity of the obstacle and host vehicle";
CM_ SG_ 1203 ObstacleVelY "The relative lateral velocity of the obstacle and host vehicle, left positive, right negative";
CM_ SG_ 1203 ObstacleAccX "The longitude absolute acceleration of the object.";
CM_ SG_ 1202 ObstacleLength "Length of obstacle, valid for vehicle and cyclist. For pedestrian output as 0.";
CM_ SG_ 1202 ObstacleWidth "Width of obstacle rear, valid for vehicle and cyclist. For pedestrian output as 0.";
CM_ SG_ 1202 ObstacleHeight "Height of obstacle, valid for vehicle, cyclist and pedestrian";
CM_ SG_ 1202 CIPVFlag "If this obstacle CIPV, closest target(vehicle and cyclist) in path. Calculated by fusion of host lane path and predicted path";
CM_ SG_ 1202 MCPFlag "If this obstacle MCP, most critical target(pedestrian). Calculated by fusion of host lane path and predicted path";
CM_ SG_ 1202 ObstacleBlinkerInfo "Turn light signal in single frame, just valid for vehicle target. ";
CM_ SG_ 1202 ObstacleBrakeLights "Brake light signal in single frame, just valid for vehicle target";
CM_ SG_ 1202 ObstacleCenterAngle "The Angle Between the orientation of Host Vehicle and the orientation from the front center of Host Vehicle  to the Reference Point of the target. Mainly used when fusion with front Radar";
CM_ SG_ 1202 ObstaclePositionType "Observation point type of the obstacle, mainly depending on the heading angle of the obstacle. For preceding or oncoming target, output as 2; for crossing or turning target, output as 7 or 8. Just valid for vehicle target";
CM_ SG_ 1202 Obstacle_TTC "eTTC value for this obstacle, calculated from target perception distance, velocity and deceleration, by the method of enhanced TTC";
CM_ SG_ 1201 ObstacleID "Object ID, valid value is 1 to 255, 0 as default. 1 to 200 for vehicle, 201 to 255 for pedestrian";
CM_ SG_ 1201 ObstacleValid "Obstacle Valid info, when target exists, 'ObstacleValid'=1 in first frame, 'ObstacleValid'=2 from second frame";
CM_ SG_ 1201 ObstacleReplaced "Reserved";
CM_ SG_ 1201 ObstacleAge "Frame age of this obstacle exists, because some post-process logic to ensure the tracking status and confidence, in the first frame maybe not be '1'";
CM_ SG_ 1201 ObstacleConfidence "Existence probability of Obstacle, calculated from CNN detection, when > 6 continuously means high conf obstacle target. ";
CM_ SG_ 1201 ObstacleMotionCategory "The signal is based on our estimation of where the target is now relatively to the lanes, its rate of change, and our estimation of where it is going to be within one second. Just valid when 'ObstacleClass'=1, vehicle target";
CM_ SG_ 1201 ObstacleMotionStatus "The target is moving or stopped. Just valid when 'ObstacleClass'=1, vehicle target";
CM_ SG_ 1201 ObstacleMeasuringStatus "Were measurements predicted, old, or not valid, 'PREDICTED' will be continuously less than 3 frames";
CM_ SG_ 1201 ObstacleClass "Classification of this object";
CM_ SG_ 1201 VehicleSubType "Vehicle Sub type, when 'ObstacleClass'=1";
CM_ SG_ 1201 PedSubType "Pedestrian Sub type, when 'ObstacleClass'=2";
CM_ SG_ 1201 PedPos "Pedestrian posture, for normal standing person, output as 'Pedestrian'. For cyclist, no further posture could be classificated";
CM_ SG_ 1201 PedOrientation "Pedestrian orientation, classification in single frame in image space";
CM_ SG_ 1201 ObstacleLaneAssignment "Obstacle Lane Assignment £¨Which lane a vehicle belongs to£©";
CM_ SG_ 1201 ObstacleOccluded "Obstacle is occluded or not in image space. Just when the obstacle was partially occluded could output as 2";
CM_ SG_ 1196 ObjCornerPointPoxX "The longitudinal distance of the obstacle's nearest coner to host vehicle in VCS. Most situation the corner point is the potential cut-in frontal corner point. Not valid for cyclist and pedestrian";
CM_ SG_ 1196 CutInDistance "The lateral relative distance of the obstacle's nearest coner to host lane line center. Positive means the vehicle now out of host lane, negative means the vehicle had been part in host lane. Not valid for cyclist and pedestrian";
CM_ SG_ 1196 ObjCornerPointPoxY "The lateral distance of the obstacle's nearest coner to host vehicle in VCS. Most situation the corner point is the potential cut-in frontal corner point. Not valid for cyclist and pedestrian";
CM_ SG_ 1196 ObstacleCurvatureRadius "Curvature radius of obstacle, the tendency of turning, calculated by single frame, mainly used when fusion with Radar";
CM_ SG_ 1196 ObstacleTrackingConfidence "Obstacle Tracking Confidence, which judged the confidence of tracking status.";
CM_ SG_ 1196 CutInFlag "Cut-in status for obstacle. Normal target output as 0; when made cut-in-hostlane action continuously output as 1; when target appeared from edge of FOV and target only partially visible output as 2. Not valid for cyclist and pedestrian";
CM_ SG_ 1195 ObstacleAngle "The heading angle of vehicle or cyclist, not valid pedestrian";
CM_ SG_ 1195 ObstacleAngleStd "The standard deviation of heading angle of obstacle, calculated from Tracking Filter";
CM_ SG_ 1195 ObstacleVelXAbs "The abusolute longitude velocity of the obstacle. ";
CM_ SG_ 1195 ObstacleVelYAbs "The abusolute lateral velocity of the obstacle. ";
CM_ SG_ 1195 RollingCounter_Obstacle16 "Rolling Counter of the msg ObstacleDataA16~ObstacleDataF16, Rolling between 0 and 15 SPI frame by SPI frame";
CM_ SG_ 1195 Checksum_Obstacle16 "CRC Checksum of the msg ObstacleDataA16~ObstacleDataF16, all the signals except Checksum_Obstacle_Signal are included. CRC4 algorithm.";
CM_ SG_ 1194 ObstaclePosXSTD "the standard deviation of longitudinal distance (ObstaclePosX) to observation point of obstacle in VCS, calculated from Tracking Filter";
CM_ SG_ 1194 ObstaclePosYSTD "the standard deviation of lateral distance (ObstaclePosY) to observation point of obstacle in VCS, calculated from Tracking Filter  ";
CM_ SG_ 1194 ObstacleVelXSTD "the standard deviation of longitude velocity (ObstacleVelX) of the obstacle, calculated from Tracking Filter  ";
CM_ SG_ 1194 ObstacleVelYSTD "the standard deviation of  lateral velocity (ObstacleVelY) of the obstacle, calculated from Tracking Filter  ";
CM_ SG_ 1194 ObstacleAccY "The lateral absolute acceleration of the object.";
CM_ SG_ 1193 ObstaclePosX "The longitudinal distance to observation point of obstacle in VCS";
CM_ SG_ 1193 ObstaclePosY "The lateral distance to observation point of obstacle in VCS, left positive, right negative";
CM_ SG_ 1193 ObstacleVelX "The relative longitude velocity of the obstacle and host vehicle";
CM_ SG_ 1193 ObstacleVelY "The relative lateral velocity of the obstacle and host vehicle, left positive, right negative";
CM_ SG_ 1193 ObstacleAccX "The longitude absolute acceleration of the object.";
CM_ SG_ 1192 ObstacleLength "Length of obstacle, valid for vehicle and cyclist. For pedestrian output as 0.";
CM_ SG_ 1192 ObstacleWidth "Width of obstacle rear, valid for vehicle and cyclist. For pedestrian output as 0.";
CM_ SG_ 1192 ObstacleHeight "Height of obstacle, valid for vehicle, cyclist and pedestrian";
CM_ SG_ 1192 CIPVFlag "If this obstacle CIPV, closest target(vehicle and cyclist) in path. Calculated by fusion of host lane path and predicted path";
CM_ SG_ 1192 MCPFlag "If this obstacle MCP, most critical target(pedestrian). Calculated by fusion of host lane path and predicted path";
CM_ SG_ 1192 ObstacleBlinkerInfo "Turn light signal in single frame, just valid for vehicle target. ";
CM_ SG_ 1192 ObstacleBrakeLights "Brake light signal in single frame, just valid for vehicle target";
CM_ SG_ 1192 ObstacleCenterAngle "The Angle Between the orientation of Host Vehicle and the orientation from the front center of Host Vehicle  to the Reference Point of the target. Mainly used when fusion with front Radar";
CM_ SG_ 1192 ObstaclePositionType "Observation point type of the obstacle, mainly depending on the heading angle of the obstacle. For preceding or oncoming target, output as 2; for crossing or turning target, output as 7 or 8. Just valid for vehicle target";
CM_ SG_ 1192 Obstacle_TTC "eTTC value for this obstacle, calculated from target perception distance, velocity and deceleration, by the method of enhanced TTC";
CM_ SG_ 1191 ObstacleID "Object ID, valid value is 1 to 255, 0 as default. 1 to 200 for vehicle, 201 to 255 for pedestrian";
CM_ SG_ 1191 ObstacleValid "Obstacle Valid info, when target exists, 'ObstacleValid'=1 in first frame, 'ObstacleValid'=2 from second frame";
CM_ SG_ 1191 ObstacleReplaced "Reserved";
CM_ SG_ 1191 ObstacleAge "Frame age of this obstacle exists, because some post-process logic to ensure the tracking status and confidence, in the first frame maybe not be '1'";
CM_ SG_ 1191 ObstacleConfidence "Existence probability of Obstacle, calculated from CNN detection, when > 6 continuously means high conf obstacle target. ";
CM_ SG_ 1191 ObstacleMotionCategory "The signal is based on our estimation of where the target is now relatively to the lanes, its rate of change, and our estimation of where it is going to be within one second. Just valid when 'ObstacleClass'=1, vehicle target";
CM_ SG_ 1191 ObstacleMotionStatus "The target is moving or stopped. Just valid when 'ObstacleClass'=1, vehicle target";
CM_ SG_ 1191 ObstacleMeasuringStatus "Were measurements predicted, old, or not valid, 'PREDICTED' will be continuously less than 3 frames";
CM_ SG_ 1191 ObstacleClass "Classification of this object";
CM_ SG_ 1191 VehicleSubType "Vehicle Sub type, when 'ObstacleClass'=1";
CM_ SG_ 1191 PedSubType "Pedestrian Sub type, when 'ObstacleClass'=2";
CM_ SG_ 1191 PedPos "Pedestrian posture, for normal standing person, output as 'Pedestrian'. For cyclist, no further posture could be classificated";
CM_ SG_ 1191 PedOrientation "Pedestrian orientation, classification in single frame in image space";
CM_ SG_ 1191 ObstacleLaneAssignment "Obstacle Lane Assignment £¨Which lane a vehicle belongs to£©";
CM_ SG_ 1191 ObstacleOccluded "Obstacle is occluded or not in image space. Just when the obstacle was partially occluded could output as 2";
CM_ SG_ 1186 ObjCornerPointPoxX "The longitudinal distance of the obstacle's nearest coner to host vehicle in VCS. Most situation the corner point is the potential cut-in frontal corner point. Not valid for cyclist and pedestrian";
CM_ SG_ 1186 CutInDistance "The lateral relative distance of the obstacle's nearest coner to host lane line center. Positive means the vehicle now out of host lane, negative means the vehicle had been part in host lane. Not valid for cyclist and pedestrian";
CM_ SG_ 1186 ObjCornerPointPoxY "The lateral distance of the obstacle's nearest coner to host vehicle in VCS. Most situation the corner point is the potential cut-in frontal corner point. Not valid for cyclist and pedestrian";
CM_ SG_ 1186 ObstacleCurvatureRadius "Curvature radius of obstacle, the tendency of turning, calculated by single frame, mainly used when fusion with Radar";
CM_ SG_ 1186 ObstacleTrackingConfidence "Obstacle Tracking Confidence, which judged the confidence of tracking status.";
CM_ SG_ 1186 CutInFlag "Cut-in status for obstacle. Normal target output as 0; when made cut-in-hostlane action continuously output as 1; when target appeared from edge of FOV and target only partially visible output as 2. Not valid for cyclist and pedestrian";
CM_ SG_ 1185 ObstacleAngle "The heading angle of vehicle or cyclist, not valid pedestrian";
CM_ SG_ 1185 ObstacleAngleStd "The standard deviation of heading angle of obstacle, calculated from Tracking Filter";
CM_ SG_ 1185 ObstacleVelXAbs "The abusolute longitude velocity of the obstacle. ";
CM_ SG_ 1185 ObstacleVelYAbs "The abusolute lateral velocity of the obstacle. ";
CM_ SG_ 1185 RollingCounter_Obstacle15 "Rolling Counter of the msg ObstacleDataA15~ObstacleDataF15, Rolling between 0 and 15 SPI frame by SPI frame";
CM_ SG_ 1185 Checksum_Obstacle15 "CRC Checksum of the msg ObstacleDataA15~ObstacleDataF15, all the signals except Checksum_Obstacle_Signal are included. CRC4 algorithm.";
CM_ SG_ 1184 ObstaclePosXSTD "the standard deviation of longitudinal distance (ObstaclePosX) to observation point of obstacle in VCS, calculated from Tracking Filter";
CM_ SG_ 1184 ObstaclePosYSTD "the standard deviation of lateral distance (ObstaclePosY) to observation point of obstacle in VCS, calculated from Tracking Filter  ";
CM_ SG_ 1184 ObstacleVelXSTD "the standard deviation of longitude velocity (ObstacleVelX) of the obstacle, calculated from Tracking Filter  ";
CM_ SG_ 1184 ObstacleVelYSTD "the standard deviation of  lateral velocity (ObstacleVelY) of the obstacle, calculated from Tracking Filter  ";
CM_ SG_ 1184 ObstacleAccY "The lateral absolute acceleration of the object.";
CM_ SG_ 1183 ObstaclePosX "The longitudinal distance to observation point of obstacle in VCS";
CM_ SG_ 1183 ObstaclePosY "The lateral distance to observation point of obstacle in VCS, left positive, right negative";
CM_ SG_ 1183 ObstacleVelX "The relative longitude velocity of the obstacle and host vehicle";
CM_ SG_ 1183 ObstacleVelY "The relative lateral velocity of the obstacle and host vehicle, left positive, right negative";
CM_ SG_ 1183 ObstacleAccX "The longitude absolute acceleration of the object.";
CM_ SG_ 1182 ObstacleLength "Length of obstacle, valid for vehicle and cyclist. For pedestrian output as 0.";
CM_ SG_ 1182 ObstacleWidth "Width of obstacle rear, valid for vehicle and cyclist. For pedestrian output as 0.";
CM_ SG_ 1182 ObstacleHeight "Height of obstacle, valid for vehicle, cyclist and pedestrian";
CM_ SG_ 1182 CIPVFlag "If this obstacle CIPV, closest target(vehicle and cyclist) in path. Calculated by fusion of host lane path and predicted path";
CM_ SG_ 1182 MCPFlag "If this obstacle MCP, most critical target(pedestrian). Calculated by fusion of host lane path and predicted path";
CM_ SG_ 1182 ObstacleBlinkerInfo "Turn light signal in single frame, just valid for vehicle target. ";
CM_ SG_ 1182 ObstacleBrakeLights "Brake light signal in single frame, just valid for vehicle target";
CM_ SG_ 1182 ObstacleCenterAngle "The Angle Between the orientation of Host Vehicle and the orientation from the front center of Host Vehicle  to the Reference Point of the target. Mainly used when fusion with front Radar";
CM_ SG_ 1182 ObstaclePositionType "Observation point type of the obstacle, mainly depending on the heading angle of the obstacle. For preceding or oncoming target, output as 2; for crossing or turning target, output as 7 or 8. Just valid for vehicle target";
CM_ SG_ 1182 Obstacle_TTC "eTTC value for this obstacle, calculated from target perception distance, velocity and deceleration, by the method of enhanced TTC";
CM_ SG_ 1181 ObstacleID "Object ID, valid value is 1 to 255, 0 as default. 1 to 200 for vehicle, 201 to 255 for pedestrian";
CM_ SG_ 1181 ObstacleValid "Obstacle Valid info, when target exists, 'ObstacleValid'=1 in first frame, 'ObstacleValid'=2 from second frame";
CM_ SG_ 1181 ObstacleReplaced "Reserved";
CM_ SG_ 1181 ObstacleAge "Frame age of this obstacle exists, because some post-process logic to ensure the tracking status and confidence, in the first frame maybe not be '1'";
CM_ SG_ 1181 ObstacleConfidence "Existence probability of Obstacle, calculated from CNN detection, when > 6 continuously means high conf obstacle target. ";
CM_ SG_ 1181 ObstacleMotionCategory "The signal is based on our estimation of where the target is now relatively to the lanes, its rate of change, and our estimation of where it is going to be within one second. Just valid when 'ObstacleClass'=1, vehicle target";
CM_ SG_ 1181 ObstacleMotionStatus "The target is moving or stopped. Just valid when 'ObstacleClass'=1, vehicle target";
CM_ SG_ 1181 ObstacleMeasuringStatus "Were measurements predicted, old, or not valid, 'PREDICTED' will be continuously less than 3 frames";
CM_ SG_ 1181 ObstacleClass "Classification of this object";
CM_ SG_ 1181 VehicleSubType "Vehicle Sub type, when 'ObstacleClass'=1";
CM_ SG_ 1181 PedSubType "Pedestrian Sub type, when 'ObstacleClass'=2";
CM_ SG_ 1181 PedPos "Pedestrian posture, for normal standing person, output as 'Pedestrian'. For cyclist, no further posture could be classificated";
CM_ SG_ 1181 PedOrientation "Pedestrian orientation, classification in single frame in image space";
CM_ SG_ 1181 ObstacleLaneAssignment "Obstacle Lane Assignment £¨Which lane a vehicle belongs to£©";
CM_ SG_ 1181 ObstacleOccluded "Obstacle is occluded or not in image space. Just when the obstacle was partially occluded could output as 2";
CM_ SG_ 1176 ObjCornerPointPoxX "The longitudinal distance of the obstacle's nearest coner to host vehicle in VCS. Most situation the corner point is the potential cut-in frontal corner point. Not valid for cyclist and pedestrian";
CM_ SG_ 1176 CutInDistance "The lateral relative distance of the obstacle's nearest coner to host lane line center. Positive means the vehicle now out of host lane, negative means the vehicle had been part in host lane. Not valid for cyclist and pedestrian";
CM_ SG_ 1176 ObjCornerPointPoxY "The lateral distance of the obstacle's nearest coner to host vehicle in VCS. Most situation the corner point is the potential cut-in frontal corner point. Not valid for cyclist and pedestrian";
CM_ SG_ 1176 ObstacleCurvatureRadius "Curvature radius of obstacle, the tendency of turning, calculated by single frame, mainly used when fusion with Radar";
CM_ SG_ 1176 ObstacleTrackingConfidence "Obstacle Tracking Confidence, which judged the confidence of tracking status.";
CM_ SG_ 1176 CutInFlag "Cut-in status for obstacle. Normal target output as 0; when made cut-in-hostlane action continuously output as 1; when target appeared from edge of FOV and target only partially visible output as 2. Not valid for cyclist and pedestrian";
CM_ SG_ 1175 ObstacleAngle "The heading angle of vehicle or cyclist, not valid pedestrian";
CM_ SG_ 1175 ObstacleAngleStd "The standard deviation of heading angle of obstacle, calculated from Tracking Filter";
CM_ SG_ 1175 ObstacleVelXAbs "The abusolute longitude velocity of the obstacle. ";
CM_ SG_ 1175 ObstacleVelYAbs "The abusolute lateral velocity of the obstacle. ";
CM_ SG_ 1175 RollingCounter_Obstacle14 "Rolling Counter of the msg ObstacleDataA14~ObstacleDataF14, Rolling between 0 and 15 SPI frame by SPI frame";
CM_ SG_ 1175 Checksum_Obstacle14 "CRC Checksum of the msg ObstacleDataA14~ObstacleDataF14, all the signals except Checksum_Obstacle_Signal are included. CRC4 algorithm.";
CM_ SG_ 1174 ObstaclePosXSTD "the standard deviation of longitudinal distance (ObstaclePosX) to observation point of obstacle in VCS, calculated from Tracking Filter";
CM_ SG_ 1174 ObstaclePosYSTD "the standard deviation of lateral distance (ObstaclePosY) to observation point of obstacle in VCS, calculated from Tracking Filter  ";
CM_ SG_ 1174 ObstacleVelXSTD "the standard deviation of longitude velocity (ObstacleVelX) of the obstacle, calculated from Tracking Filter  ";
CM_ SG_ 1174 ObstacleVelYSTD "the standard deviation of  lateral velocity (ObstacleVelY) of the obstacle, calculated from Tracking Filter  ";
CM_ SG_ 1174 ObstacleAccY "The lateral absolute acceleration of the object.";
CM_ SG_ 1173 ObstaclePosX "The longitudinal distance to observation point of obstacle in VCS";
CM_ SG_ 1173 ObstaclePosY "The lateral distance to observation point of obstacle in VCS, left positive, right negative";
CM_ SG_ 1173 ObstacleVelX "The relative longitude velocity of the obstacle and host vehicle";
CM_ SG_ 1173 ObstacleVelY "The relative lateral velocity of the obstacle and host vehicle, left positive, right negative";
CM_ SG_ 1173 ObstacleAccX "The longitude absolute acceleration of the object.";
CM_ SG_ 1172 ObstacleLength "Length of obstacle, valid for vehicle and cyclist. For pedestrian output as 0.";
CM_ SG_ 1172 ObstacleWidth "Width of obstacle rear, valid for vehicle and cyclist. For pedestrian output as 0.";
CM_ SG_ 1172 ObstacleHeight "Height of obstacle, valid for vehicle, cyclist and pedestrian";
CM_ SG_ 1172 CIPVFlag "If this obstacle CIPV, closest target(vehicle and cyclist) in path. Calculated by fusion of host lane path and predicted path";
CM_ SG_ 1172 MCPFlag "If this obstacle MCP, most critical target(pedestrian). Calculated by fusion of host lane path and predicted path";
CM_ SG_ 1172 ObstacleBlinkerInfo "Turn light signal in single frame, just valid for vehicle target. ";
CM_ SG_ 1172 ObstacleBrakeLights "Brake light signal in single frame, just valid for vehicle target";
CM_ SG_ 1172 ObstacleCenterAngle "The Angle Between the orientation of Host Vehicle and the orientation from the front center of Host Vehicle  to the Reference Point of the target. Mainly used when fusion with front Radar";
CM_ SG_ 1172 ObstaclePositionType "Observation point type of the obstacle, mainly depending on the heading angle of the obstacle. For preceding or oncoming target, output as 2; for crossing or turning target, output as 7 or 8. Just valid for vehicle target";
CM_ SG_ 1172 Obstacle_TTC "eTTC value for this obstacle, calculated from target perception distance, velocity and deceleration, by the method of enhanced TTC";
CM_ SG_ 1171 ObstacleID "Object ID, valid value is 1 to 255, 0 as default. 1 to 200 for vehicle, 201 to 255 for pedestrian";
CM_ SG_ 1171 ObstacleValid "Obstacle Valid info, when target exists, 'ObstacleValid'=1 in first frame, 'ObstacleValid'=2 from second frame";
CM_ SG_ 1171 ObstacleReplaced "Reserved";
CM_ SG_ 1171 ObstacleAge "Frame age of this obstacle exists, because some post-process logic to ensure the tracking status and confidence, in the first frame maybe not be '1'";
CM_ SG_ 1171 ObstacleConfidence "Existence probability of Obstacle, calculated from CNN detection, when > 6 continuously means high conf obstacle target. ";
CM_ SG_ 1171 ObstacleMotionCategory "The signal is based on our estimation of where the target is now relatively to the lanes, its rate of change, and our estimation of where it is going to be within one second. Just valid when 'ObstacleClass'=1, vehicle target";
CM_ SG_ 1171 ObstacleMotionStatus "The target is moving or stopped. Just valid when 'ObstacleClass'=1, vehicle target";
CM_ SG_ 1171 ObstacleMeasuringStatus "Were measurements predicted, old, or not valid, 'PREDICTED' will be continuously less than 3 frames";
CM_ SG_ 1171 ObstacleClass "Classification of this object";
CM_ SG_ 1171 VehicleSubType "Vehicle Sub type, when 'ObstacleClass'=1";
CM_ SG_ 1171 PedSubType "Pedestrian Sub type, when 'ObstacleClass'=2";
CM_ SG_ 1171 PedPos "Pedestrian posture, for normal standing person, output as 'Pedestrian'. For cyclist, no further posture could be classificated";
CM_ SG_ 1171 PedOrientation "Pedestrian orientation, classification in single frame in image space";
CM_ SG_ 1171 ObstacleLaneAssignment "Obstacle Lane Assignment £¨Which lane a vehicle belongs to£©";
CM_ SG_ 1171 ObstacleOccluded "Obstacle is occluded or not in image space. Just when the obstacle was partially occluded could output as 2";
CM_ SG_ 1166 ObjCornerPointPoxX "The longitudinal distance of the obstacle's nearest coner to host vehicle in VCS. Most situation the corner point is the potential cut-in frontal corner point. Not valid for cyclist and pedestrian";
CM_ SG_ 1166 CutInDistance "The lateral relative distance of the obstacle's nearest coner to host lane line center. Positive means the vehicle now out of host lane, negative means the vehicle had been part in host lane. Not valid for cyclist and pedestrian";
CM_ SG_ 1166 ObjCornerPointPoxY "The lateral distance of the obstacle's nearest coner to host vehicle in VCS. Most situation the corner point is the potential cut-in frontal corner point. Not valid for cyclist and pedestrian";
CM_ SG_ 1166 ObstacleCurvatureRadius "Curvature radius of obstacle, the tendency of turning, calculated by single frame, mainly used when fusion with Radar";
CM_ SG_ 1166 ObstacleTrackingConfidence "Obstacle Tracking Confidence, which judged the confidence of tracking status.";
CM_ SG_ 1166 CutInFlag "Cut-in status for obstacle. Normal target output as 0; when made cut-in-hostlane action continuously output as 1; when target appeared from edge of FOV and target only partially visible output as 2. Not valid for cyclist and pedestrian";
CM_ SG_ 1165 ObstacleAngle "The heading angle of vehicle or cyclist, not valid pedestrian";
CM_ SG_ 1165 ObstacleAngleStd "The standard deviation of heading angle of obstacle, calculated from Tracking Filter";
CM_ SG_ 1165 ObstacleVelXAbs "The abusolute longitude velocity of the obstacle. ";
CM_ SG_ 1165 ObstacleVelYAbs "The abusolute lateral velocity of the obstacle. ";
CM_ SG_ 1165 RollingCounter_Obstacle13 "Rolling Counter of the msg ObstacleDataA13~ObstacleDataF13, Rolling between 0 and 15 SPI frame by SPI frame";
CM_ SG_ 1165 Checksum_Obstacle13 "CRC Checksum of the msg ObstacleDataA13~ObstacleDataF13, all the signals except Checksum_Obstacle_Signal are included. CRC4 algorithm.";
CM_ SG_ 1164 ObstaclePosXSTD "the standard deviation of longitudinal distance (ObstaclePosX) to observation point of obstacle in VCS, calculated from Tracking Filter";
CM_ SG_ 1164 ObstaclePosYSTD "the standard deviation of lateral distance (ObstaclePosY) to observation point of obstacle in VCS, calculated from Tracking Filter  ";
CM_ SG_ 1164 ObstacleVelXSTD "the standard deviation of longitude velocity (ObstacleVelX) of the obstacle, calculated from Tracking Filter  ";
CM_ SG_ 1164 ObstacleVelYSTD "the standard deviation of  lateral velocity (ObstacleVelY) of the obstacle, calculated from Tracking Filter  ";
CM_ SG_ 1164 ObstacleAccY "The lateral absolute acceleration of the object.";
CM_ SG_ 1163 ObstaclePosX "The longitudinal distance to observation point of obstacle in VCS";
CM_ SG_ 1163 ObstaclePosY "The lateral distance to observation point of obstacle in VCS, left positive, right negative";
CM_ SG_ 1163 ObstacleVelX "The relative longitude velocity of the obstacle and host vehicle";
CM_ SG_ 1163 ObstacleVelY "The relative lateral velocity of the obstacle and host vehicle, left positive, right negative";
CM_ SG_ 1163 ObstacleAccX "The longitude absolute acceleration of the object.";
CM_ SG_ 1162 ObstacleLength "Length of obstacle, valid for vehicle and cyclist. For pedestrian output as 0.";
CM_ SG_ 1162 ObstacleWidth "Width of obstacle rear, valid for vehicle and cyclist. For pedestrian output as 0.";
CM_ SG_ 1162 ObstacleHeight "Height of obstacle, valid for vehicle, cyclist and pedestrian";
CM_ SG_ 1162 CIPVFlag "If this obstacle CIPV, closest target(vehicle and cyclist) in path. Calculated by fusion of host lane path and predicted path";
CM_ SG_ 1162 MCPFlag "If this obstacle MCP, most critical target(pedestrian). Calculated by fusion of host lane path and predicted path";
CM_ SG_ 1162 ObstacleBlinkerInfo "Turn light signal in single frame, just valid for vehicle target. ";
CM_ SG_ 1162 ObstacleBrakeLights "Brake light signal in single frame, just valid for vehicle target";
CM_ SG_ 1162 ObstacleCenterAngle "The Angle Between the orientation of Host Vehicle and the orientation from the front center of Host Vehicle  to the Reference Point of the target. Mainly used when fusion with front Radar";
CM_ SG_ 1162 ObstaclePositionType "Observation point type of the obstacle, mainly depending on the heading angle of the obstacle. For preceding or oncoming target, output as 2; for crossing or turning target, output as 7 or 8. Just valid for vehicle target";
CM_ SG_ 1162 Obstacle_TTC "eTTC value for this obstacle, calculated from target perception distance, velocity and deceleration, by the method of enhanced TTC";
CM_ SG_ 1161 ObstacleID "Object ID, valid value is 1 to 255, 0 as default. 1 to 200 for vehicle, 201 to 255 for pedestrian";
CM_ SG_ 1161 ObstacleValid "Obstacle Valid info, when target exists, 'ObstacleValid'=1 in first frame, 'ObstacleValid'=2 from second frame";
CM_ SG_ 1161 ObstacleReplaced "Reserved";
CM_ SG_ 1161 ObstacleAge "Frame age of this obstacle exists, because some post-process logic to ensure the tracking status and confidence, in the first frame maybe not be '1'";
CM_ SG_ 1161 ObstacleConfidence "Existence probability of Obstacle, calculated from CNN detection, when > 6 continuously means high conf obstacle target. ";
CM_ SG_ 1161 ObstacleMotionCategory "The signal is based on our estimation of where the target is now relatively to the lanes, its rate of change, and our estimation of where it is going to be within one second. Just valid when 'ObstacleClass'=1, vehicle target";
CM_ SG_ 1161 ObstacleMotionStatus "The target is moving or stopped. Just valid when 'ObstacleClass'=1, vehicle target";
CM_ SG_ 1161 ObstacleMeasuringStatus "Were measurements predicted, old, or not valid, 'PREDICTED' will be continuously less than 3 frames";
CM_ SG_ 1161 ObstacleClass "Classification of this object";
CM_ SG_ 1161 VehicleSubType "Vehicle Sub type, when 'ObstacleClass'=1";
CM_ SG_ 1161 PedSubType "Pedestrian Sub type, when 'ObstacleClass'=2";
CM_ SG_ 1161 PedPos "Pedestrian posture, for normal standing person, output as 'Pedestrian'. For cyclist, no further posture could be classificated";
CM_ SG_ 1161 PedOrientation "Pedestrian orientation, classification in single frame in image space";
CM_ SG_ 1161 ObstacleLaneAssignment "Obstacle Lane Assignment £¨Which lane a vehicle belongs to£©";
CM_ SG_ 1161 ObstacleOccluded "Obstacle is occluded or not in image space. Just when the obstacle was partially occluded could output as 2";
CM_ SG_ 1156 ObjCornerPointPoxX "The longitudinal distance of the obstacle's nearest coner to host vehicle in VCS. Most situation the corner point is the potential cut-in frontal corner point. Not valid for cyclist and pedestrian";
CM_ SG_ 1156 CutInDistance "The lateral relative distance of the obstacle's nearest coner to host lane line center. Positive means the vehicle now out of host lane, negative means the vehicle had been part in host lane. Not valid for cyclist and pedestrian";
CM_ SG_ 1156 ObjCornerPointPoxY "The lateral distance of the obstacle's nearest coner to host vehicle in VCS. Most situation the corner point is the potential cut-in frontal corner point. Not valid for cyclist and pedestrian";
CM_ SG_ 1156 ObstacleCurvatureRadius "Curvature radius of obstacle, the tendency of turning, calculated by single frame, mainly used when fusion with Radar";
CM_ SG_ 1156 ObstacleTrackingConfidence "Obstacle Tracking Confidence, which judged the confidence of tracking status.";
CM_ SG_ 1156 CutInFlag "Cut-in status for obstacle. Normal target output as 0; when made cut-in-hostlane action continuously output as 1; when target appeared from edge of FOV and target only partially visible output as 2. Not valid for cyclist and pedestrian";
CM_ SG_ 1155 ObstacleAngle "The heading angle of vehicle or cyclist, not valid pedestrian";
CM_ SG_ 1155 ObstacleAngleStd "The standard deviation of heading angle of obstacle, calculated from Tracking Filter";
CM_ SG_ 1155 ObstacleVelXAbs "The abusolute longitude velocity of the obstacle. ";
CM_ SG_ 1155 ObstacleVelYAbs "The abusolute lateral velocity of the obstacle. ";
CM_ SG_ 1155 RollingCounter_Obstacle12 "Rolling Counter of the msg ObstacleDataA12~ObstacleDataF12, Rolling between 0 and 15 SPI frame by SPI frame";
CM_ SG_ 1155 Checksum_Obstacle12 "CRC Checksum of the msg ObstacleDataA12~ObstacleDataF12, all the signals except Checksum_Obstacle_Signal are included. CRC4 algorithm.";
CM_ SG_ 1154 ObstaclePosXSTD "the standard deviation of longitudinal distance (ObstaclePosX) to observation point of obstacle in VCS, calculated from Tracking Filter";
CM_ SG_ 1154 ObstaclePosYSTD "the standard deviation of lateral distance (ObstaclePosY) to observation point of obstacle in VCS, calculated from Tracking Filter  ";
CM_ SG_ 1154 ObstacleVelXSTD "the standard deviation of longitude velocity (ObstacleVelX) of the obstacle, calculated from Tracking Filter  ";
CM_ SG_ 1154 ObstacleVelYSTD "the standard deviation of  lateral velocity (ObstacleVelY) of the obstacle, calculated from Tracking Filter  ";
CM_ SG_ 1154 ObstacleAccY "The lateral absolute acceleration of the object.";
CM_ SG_ 1153 ObstaclePosX "The longitudinal distance to observation point of obstacle in VCS";
CM_ SG_ 1153 ObstaclePosY "The lateral distance to observation point of obstacle in VCS, left positive, right negative";
CM_ SG_ 1153 ObstacleVelX "The relative longitude velocity of the obstacle and host vehicle";
CM_ SG_ 1153 ObstacleVelY "The relative lateral velocity of the obstacle and host vehicle, left positive, right negative";
CM_ SG_ 1153 ObstacleAccX "The longitude absolute acceleration of the object.";
CM_ SG_ 1152 ObstacleLength "Length of obstacle, valid for vehicle and cyclist. For pedestrian output as 0.";
CM_ SG_ 1152 ObstacleWidth "Width of obstacle rear, valid for vehicle and cyclist. For pedestrian output as 0.";
CM_ SG_ 1152 ObstacleHeight "Height of obstacle, valid for vehicle, cyclist and pedestrian";
CM_ SG_ 1152 CIPVFlag "If this obstacle CIPV, closest target(vehicle and cyclist) in path. Calculated by fusion of host lane path and predicted path";
CM_ SG_ 1152 MCPFlag "If this obstacle MCP, most critical target(pedestrian). Calculated by fusion of host lane path and predicted path";
CM_ SG_ 1152 ObstacleBlinkerInfo "Turn light signal in single frame, just valid for vehicle target. ";
CM_ SG_ 1152 ObstacleBrakeLights "Brake light signal in single frame, just valid for vehicle target";
CM_ SG_ 1152 ObstacleCenterAngle "The Angle Between the orientation of Host Vehicle and the orientation from the front center of Host Vehicle  to the Reference Point of the target. Mainly used when fusion with front Radar";
CM_ SG_ 1152 ObstaclePositionType "Observation point type of the obstacle, mainly depending on the heading angle of the obstacle. For preceding or oncoming target, output as 2; for crossing or turning target, output as 7 or 8. Just valid for vehicle target";
CM_ SG_ 1152 Obstacle_TTC "eTTC value for this obstacle, calculated from target perception distance, velocity and deceleration, by the method of enhanced TTC";
CM_ SG_ 1151 ObstacleID "Object ID, valid value is 1 to 255, 0 as default. 1 to 200 for vehicle, 201 to 255 for pedestrian";
CM_ SG_ 1151 ObstacleValid "Obstacle Valid info, when target exists, 'ObstacleValid'=1 in first frame, 'ObstacleValid'=2 from second frame";
CM_ SG_ 1151 ObstacleReplaced "Reserved";
CM_ SG_ 1151 ObstacleAge "Frame age of this obstacle exists, because some post-process logic to ensure the tracking status and confidence, in the first frame maybe not be '1'";
CM_ SG_ 1151 ObstacleConfidence "Existence probability of Obstacle, calculated from CNN detection, when > 6 continuously means high conf obstacle target. ";
CM_ SG_ 1151 ObstacleMotionCategory "The signal is based on our estimation of where the target is now relatively to the lanes, its rate of change, and our estimation of where it is going to be within one second. Just valid when 'ObstacleClass'=1, vehicle target";
CM_ SG_ 1151 ObstacleMotionStatus "The target is moving or stopped. Just valid when 'ObstacleClass'=1, vehicle target";
CM_ SG_ 1151 ObstacleMeasuringStatus "Were measurements predicted, old, or not valid, 'PREDICTED' will be continuously less than 3 frames";
CM_ SG_ 1151 ObstacleClass "Classification of this object";
CM_ SG_ 1151 VehicleSubType "Vehicle Sub type, when 'ObstacleClass'=1";
CM_ SG_ 1151 PedSubType "Pedestrian Sub type, when 'ObstacleClass'=2";
CM_ SG_ 1151 PedPos "Pedestrian posture, for normal standing person, output as 'Pedestrian'. For cyclist, no further posture could be classificated";
CM_ SG_ 1151 PedOrientation "Pedestrian orientation, classification in single frame in image space";
CM_ SG_ 1151 ObstacleLaneAssignment "Obstacle Lane Assignment £¨Which lane a vehicle belongs to£©";
CM_ SG_ 1151 ObstacleOccluded "Obstacle is occluded or not in image space. Just when the obstacle was partially occluded could output as 2";
CM_ SG_ 1146 ObjCornerPointPoxX "The longitudinal distance of the obstacle's nearest coner to host vehicle in VCS. Most situation the corner point is the potential cut-in frontal corner point. Not valid for cyclist and pedestrian";
CM_ SG_ 1146 CutInDistance "The lateral relative distance of the obstacle's nearest coner to host lane line center. Positive means the vehicle now out of host lane, negative means the vehicle had been part in host lane. Not valid for cyclist and pedestrian";
CM_ SG_ 1146 ObjCornerPointPoxY "The lateral distance of the obstacle's nearest coner to host vehicle in VCS. Most situation the corner point is the potential cut-in frontal corner point. Not valid for cyclist and pedestrian";
CM_ SG_ 1146 ObstacleCurvatureRadius "Curvature radius of obstacle, the tendency of turning, calculated by single frame, mainly used when fusion with Radar";
CM_ SG_ 1146 ObstacleTrackingConfidence "Obstacle Tracking Confidence, which judged the confidence of tracking status.";
CM_ SG_ 1146 CutInFlag "Cut-in status for obstacle. Normal target output as 0; when made cut-in-hostlane action continuously output as 1; when target appeared from edge of FOV and target only partially visible output as 2. Not valid for cyclist and pedestrian";
CM_ SG_ 1145 ObstacleAngle "The heading angle of vehicle or cyclist, not valid pedestrian";
CM_ SG_ 1145 ObstacleAngleStd "The standard deviation of heading angle of obstacle, calculated from Tracking Filter";
CM_ SG_ 1145 ObstacleVelXAbs "The abusolute longitude velocity of the obstacle. ";
CM_ SG_ 1145 ObstacleVelYAbs "The abusolute lateral velocity of the obstacle. ";
CM_ SG_ 1145 RollingCounter_Obstacle11 "Rolling Counter of the msg ObstacleDataA11~ObstacleDataF11, Rolling between 0 and 15 SPI frame by SPI frame";
CM_ SG_ 1145 Checksum_Obstacle11 "CRC Checksum of the msg ObstacleDataA11~ObstacleDataF11, all the signals except Checksum_Obstacle_Signal are included. CRC4 algorithm.";
CM_ SG_ 1144 ObstaclePosXSTD "the standard deviation of longitudinal distance (ObstaclePosX) to observation point of obstacle in VCS, calculated from Tracking Filter";
CM_ SG_ 1144 ObstaclePosYSTD "the standard deviation of lateral distance (ObstaclePosY) to observation point of obstacle in VCS, calculated from Tracking Filter  ";
CM_ SG_ 1144 ObstacleVelXSTD "the standard deviation of longitude velocity (ObstacleVelX) of the obstacle, calculated from Tracking Filter  ";
CM_ SG_ 1144 ObstacleVelYSTD "the standard deviation of  lateral velocity (ObstacleVelY) of the obstacle, calculated from Tracking Filter  ";
CM_ SG_ 1144 ObstacleAccY "The lateral absolute acceleration of the object.";
CM_ SG_ 1143 ObstaclePosX "The longitudinal distance to observation point of obstacle in VCS";
CM_ SG_ 1143 ObstaclePosY "The lateral distance to observation point of obstacle in VCS, left positive, right negative";
CM_ SG_ 1143 ObstacleVelX "The relative longitude velocity of the obstacle and host vehicle";
CM_ SG_ 1143 ObstacleVelY "The relative lateral velocity of the obstacle and host vehicle, left positive, right negative";
CM_ SG_ 1143 ObstacleAccX "The longitude absolute acceleration of the object.";
CM_ SG_ 1142 ObstacleLength "Length of obstacle, valid for vehicle and cyclist. For pedestrian output as 0.";
CM_ SG_ 1142 ObstacleWidth "Width of obstacle rear, valid for vehicle and cyclist. For pedestrian output as 0.";
CM_ SG_ 1142 ObstacleHeight "Height of obstacle, valid for vehicle, cyclist and pedestrian";
CM_ SG_ 1142 CIPVFlag "If this obstacle CIPV, closest target(vehicle and cyclist) in path. Calculated by fusion of host lane path and predicted path";
CM_ SG_ 1142 MCPFlag "If this obstacle MCP, most critical target(pedestrian). Calculated by fusion of host lane path and predicted path";
CM_ SG_ 1142 ObstacleBlinkerInfo "Turn light signal in single frame, just valid for vehicle target. ";
CM_ SG_ 1142 ObstacleBrakeLights "Brake light signal in single frame, just valid for vehicle target";
CM_ SG_ 1142 ObstacleCenterAngle "The Angle Between the orientation of Host Vehicle and the orientation from the front center of Host Vehicle  to the Reference Point of the target. Mainly used when fusion with front Radar";
CM_ SG_ 1142 ObstaclePositionType "Observation point type of the obstacle, mainly depending on the heading angle of the obstacle. For preceding or oncoming target, output as 2; for crossing or turning target, output as 7 or 8. Just valid for vehicle target";
CM_ SG_ 1142 Obstacle_TTC "eTTC value for this obstacle, calculated from target perception distance, velocity and deceleration, by the method of enhanced TTC";
CM_ SG_ 1141 ObstacleID "Object ID, valid value is 1 to 255, 0 as default. 1 to 200 for vehicle, 201 to 255 for pedestrian";
CM_ SG_ 1141 ObstacleValid "Obstacle Valid info, when target exists, 'ObstacleValid'=1 in first frame, 'ObstacleValid'=2 from second frame";
CM_ SG_ 1141 ObstacleReplaced "Reserved";
CM_ SG_ 1141 ObstacleAge "Frame age of this obstacle exists, because some post-process logic to ensure the tracking status and confidence, in the first frame maybe not be '1'";
CM_ SG_ 1141 ObstacleConfidence "Existence probability of Obstacle, calculated from CNN detection, when > 6 continuously means high conf obstacle target. ";
CM_ SG_ 1141 ObstacleMotionCategory "The signal is based on our estimation of where the target is now relatively to the lanes, its rate of change, and our estimation of where it is going to be within one second. Just valid when 'ObstacleClass'=1, vehicle target";
CM_ SG_ 1141 ObstacleMotionStatus "The target is moving or stopped. Just valid when 'ObstacleClass'=1, vehicle target";
CM_ SG_ 1141 ObstacleMeasuringStatus "Were measurements predicted, old, or not valid, 'PREDICTED' will be continuously less than 3 frames";
CM_ SG_ 1141 ObstacleClass "Classification of this object";
CM_ SG_ 1141 VehicleSubType "Vehicle Sub type, when 'ObstacleClass'=1";
CM_ SG_ 1141 PedSubType "Pedestrian Sub type, when 'ObstacleClass'=2";
CM_ SG_ 1141 PedPos "Pedestrian posture, for normal standing person, output as 'Pedestrian'. For cyclist, no further posture could be classificated";
CM_ SG_ 1141 PedOrientation "Pedestrian orientation, classification in single frame in image space";
CM_ SG_ 1141 ObstacleLaneAssignment "Obstacle Lane Assignment £¨Which lane a vehicle belongs to£©";
CM_ SG_ 1141 ObstacleOccluded "Obstacle is occluded or not in image space. Just when the obstacle was partially occluded could output as 2";
CM_ SG_ 1136 ObjCornerPointPoxX "The longitudinal distance of the obstacle's nearest coner to host vehicle in VCS. Most situation the corner point is the potential cut-in frontal corner point. Not valid for cyclist and pedestrian";
CM_ SG_ 1136 CutInDistance "The lateral relative distance of the obstacle's nearest coner to host lane line center. Positive means the vehicle now out of host lane, negative means the vehicle had been part in host lane. Not valid for cyclist and pedestrian";
CM_ SG_ 1136 ObjCornerPointPoxY "The lateral distance of the obstacle's nearest coner to host vehicle in VCS. Most situation the corner point is the potential cut-in frontal corner point. Not valid for cyclist and pedestrian";
CM_ SG_ 1136 ObstacleCurvatureRadius "Curvature radius of obstacle, the tendency of turning, calculated by single frame, mainly used when fusion with Radar";
CM_ SG_ 1136 ObstacleTrackingConfidence "Obstacle Tracking Confidence, which judged the confidence of tracking status.";
CM_ SG_ 1136 CutInFlag "Cut-in status for obstacle. Normal target output as 0; when made cut-in-hostlane action continuously output as 1; when target appeared from edge of FOV and target only partially visible output as 2. Not valid for cyclist and pedestrian";
CM_ SG_ 1135 ObstacleAngle "The heading angle of vehicle or cyclist, not valid pedestrian";
CM_ SG_ 1135 ObstacleAngleStd "The standard deviation of heading angle of obstacle, calculated from Tracking Filter";
CM_ SG_ 1135 ObstacleVelXAbs "The abusolute longitude velocity of the obstacle. ";
CM_ SG_ 1135 ObstacleVelYAbs "The abusolute lateral velocity of the obstacle. ";
CM_ SG_ 1135 RollingCounter_Obstacle10 "Rolling Counter of the msg ObstacleDataA10~ObstacleDataF10, Rolling between 0 and 15 SPI frame by SPI frame";
CM_ SG_ 1135 Checksum_Obstacle10 "CRC Checksum of the msg ObstacleDataA10~ObstacleDataF10, all the signals except Checksum_Obstacle_Signal are included. CRC4 algorithm.";
CM_ SG_ 1134 ObstaclePosXSTD "the standard deviation of longitudinal distance (ObstaclePosX) to observation point of obstacle in VCS, calculated from Tracking Filter";
CM_ SG_ 1134 ObstaclePosYSTD "the standard deviation of lateral distance (ObstaclePosY) to observation point of obstacle in VCS, calculated from Tracking Filter  ";
CM_ SG_ 1134 ObstacleVelXSTD "the standard deviation of longitude velocity (ObstacleVelX) of the obstacle, calculated from Tracking Filter  ";
CM_ SG_ 1134 ObstacleVelYSTD "the standard deviation of  lateral velocity (ObstacleVelY) of the obstacle, calculated from Tracking Filter  ";
CM_ SG_ 1134 ObstacleAccY "The lateral absolute acceleration of the object.";
CM_ SG_ 1133 ObstaclePosX "The longitudinal distance to observation point of obstacle in VCS";
CM_ SG_ 1133 ObstaclePosY "The lateral distance to observation point of obstacle in VCS, left positive, right negative";
CM_ SG_ 1133 ObstacleVelX "The relative longitude velocity of the obstacle and host vehicle";
CM_ SG_ 1133 ObstacleVelY "The relative lateral velocity of the obstacle and host vehicle, left positive, right negative";
CM_ SG_ 1133 ObstacleAccX "The longitude absolute acceleration of the object.";
CM_ SG_ 1132 ObstacleLength "Length of obstacle, valid for vehicle and cyclist. For pedestrian output as 0.";
CM_ SG_ 1132 ObstacleWidth "Width of obstacle rear, valid for vehicle and cyclist. For pedestrian output as 0.";
CM_ SG_ 1132 ObstacleHeight "Height of obstacle, valid for vehicle, cyclist and pedestrian";
CM_ SG_ 1132 CIPVFlag "If this obstacle CIPV, closest target(vehicle and cyclist) in path. Calculated by fusion of host lane path and predicted path";
CM_ SG_ 1132 MCPFlag "If this obstacle MCP, most critical target(pedestrian). Calculated by fusion of host lane path and predicted path";
CM_ SG_ 1132 ObstacleBlinkerInfo "Turn light signal in single frame, just valid for vehicle target. ";
CM_ SG_ 1132 ObstacleBrakeLights "Brake light signal in single frame, just valid for vehicle target";
CM_ SG_ 1132 ObstacleCenterAngle "The Angle Between the orientation of Host Vehicle and the orientation from the front center of Host Vehicle  to the Reference Point of the target. Mainly used when fusion with front Radar";
CM_ SG_ 1132 ObstaclePositionType "Observation point type of the obstacle, mainly depending on the heading angle of the obstacle. For preceding or oncoming target, output as 2; for crossing or turning target, output as 7 or 8. Just valid for vehicle target";
CM_ SG_ 1132 Obstacle_TTC "eTTC value for this obstacle, calculated from target perception distance, velocity and deceleration, by the method of enhanced TTC";
BA_DEF_  "BusType" STRING ;
BA_DEF_DEF_  "BusType" "CAN";
VAL_ 1040 CIPV_TTC_Valid 1 "Valid" 0 "NotValid" ;
VAL_ 1040 MCP_TTC_Valid 1 "Valid" 0 "NotValid" ;
VAL_ 1040 CIPV_HWM_Valid 1 "Valid" 0 "NotValid" ;
VAL_ 1236 CutInFlag 2 "close cut in" 1 "cut in" 0 "not cut in" ;
VAL_ 1232 CIPVFlag 1 "CIPV" 0 "not CIPV" ;
VAL_ 1232 MCPFlag 1 "MCP" 0 "not MCP" ;
VAL_ 1232 ObstacleBlinkerInfo 4 "Both" 3 "Right" 2 "Left" 1 "Off" 0 "Unavailable" ;
VAL_ 1232 ObstacleBrakeLights 1 "ON" 0 "OFF" ;
VAL_ 1232 ObstaclePositionType 9 "Center" 8 "RightCenter" 7 "LeftCenter" 6 "FrontRight" 5 "FrontCenter" 4 "FrontLeft" 3 "RearRight" 2 "RearCenter" 1 "RearLeft   " 0 "Unknown    " ;
VAL_ 1231 ObstacleValid 2 "older valid" 1 "new valid (detected this frame)" 0 "invalid Obstacle(default value)" ;
VAL_ 1231 ObstacleReplaced 1 "replaced in this frame" 0 "not replaced in this frame" ;
VAL_ 1231 ObstacleMotionCategory 13 "ONCOMING" 12 "PRECEEDING" 11 "MOVING" 10 "RTAP" 9 "LTAP" 8 "CROSSING" 7 "MOVING_OUT" 6 "MOVING_IN" 5 "CLOSE_CUT_IN" 4 "PASSING_OUT" 3 "PASSING_IN" 2 "PASSING" 1 "UNDEFINED" 0 "INVALID" ;
VAL_ 1231 ObstacleMotionStatus 5 "MOVING SLOWLY" 4 "STOPPED" 3 "STATIONARY" 2 "MOVING" 1 "UNKNOWN" 0 "INVALID" ;
VAL_ 1231 ObstacleMeasuringStatus 2 "PREDICTED" 1 "MEASURED" 0 "INVALID" ;
VAL_ 1231 ObstacleClass 4 "GENERAL_OBJECT(reserved)" 3 "CYCLIST" 2 "PEDESTRIAN" 1 "VEHICLE" 0 "INVALID" ;
VAL_ 1231 VehicleSubType 7 "Lorry" 6 "Tiny_car" 5 "Special_vehicle" 4 "Motors(Tri-cycle)" 3 "Trucks" 2 "Small_Medium_Car" 1 "Bus" 0 "Unknown" ;
VAL_ 1231 PedSubType 2 "Child" 1 "Adult" 0 "Unknown" ;
VAL_ 1231 PedPos 5 "Sitter" 4 "Pedestrian" 3 "Lier" 2 "Cyclist" 1 "Bended" 0 "Unknown" ;
VAL_ 1231 PedOrientation 8 "right_back" 7 "right_front" 6 "right" 5 "left_back" 4 "left_front" 3 "left" 2 "front" 1 "back" 0 "Unknown" ;
VAL_ 1231 ObstacleLaneAssignment 5 "RIGHT_RIGHT" 4 "RIGHT " 3 "HOST" 2 "LEFT" 1 "LEFT_LEFT" 0 "UNKNOWN" ;
VAL_ 1231 ObstacleOccluded 2 "Obstacle occluded" 1 "Obstacle not occluded" 0 "Default" ;
VAL_ 1226 CutInFlag 2 "close cut in" 1 "cut in" 0 "not cut in" ;
VAL_ 1222 CIPVFlag 1 "CIPV" 0 "not CIPV" ;
VAL_ 1222 MCPFlag 1 "MCP" 0 "not MCP" ;
VAL_ 1222 ObstacleBlinkerInfo 4 "Both" 3 "Right" 2 "Left" 1 "Off" 0 "Unavailable" ;
VAL_ 1222 ObstacleBrakeLights 1 "ON" 0 "OFF" ;
VAL_ 1222 ObstaclePositionType 9 "Center" 8 "RightCenter" 7 "LeftCenter" 6 "FrontRight" 5 "FrontCenter" 4 "FrontLeft" 3 "RearRight" 2 "RearCenter" 1 "RearLeft   " 0 "Unknown    " ;
VAL_ 1221 ObstacleValid 2 "older valid" 1 "new valid (detected this frame)" 0 "invalid Obstacle(default value)" ;
VAL_ 1221 ObstacleReplaced 1 "replaced in this frame" 0 "not replaced in this frame" ;
VAL_ 1221 ObstacleMotionCategory 13 "ONCOMING" 12 "PRECEEDING" 11 "MOVING" 10 "RTAP" 9 "LTAP" 8 "CROSSING" 7 "MOVING_OUT" 6 "MOVING_IN" 5 "CLOSE_CUT_IN" 4 "PASSING_OUT" 3 "PASSING_IN" 2 "PASSING" 1 "UNDEFINED" 0 "INVALID" ;
VAL_ 1221 ObstacleMotionStatus 5 "MOVING SLOWLY" 4 "STOPPED" 3 "STATIONARY" 2 "MOVING" 1 "UNKNOWN" 0 "INVALID" ;
VAL_ 1221 ObstacleMeasuringStatus 2 "PREDICTED" 1 "MEASURED" 0 "INVALID" ;
VAL_ 1221 ObstacleClass 4 "GENERAL_OBJECT(reserved)" 3 "CYCLIST" 2 "PEDESTRIAN" 1 "VEHICLE" 0 "INVALID" ;
VAL_ 1221 VehicleSubType 7 "Lorry" 6 "Tiny_car" 5 "Special_vehicle" 4 "Motors(Tri-cycle)" 3 "Trucks" 2 "Small_Medium_Car" 1 "Bus" 0 "Unknown" ;
VAL_ 1221 PedSubType 2 "Child" 1 "Adult" 0 "Unknown" ;
VAL_ 1221 PedPos 5 "Sitter" 4 "Pedestrian" 3 "Lier" 2 "Cyclist" 1 "Bended" 0 "Unknown" ;
VAL_ 1221 PedOrientation 8 "right_back" 7 "right_front" 6 "right" 5 "left_back" 4 "left_front" 3 "left" 2 "front" 1 "back" 0 "Unknown" ;
VAL_ 1221 ObstacleLaneAssignment 5 "RIGHT_RIGHT" 4 "RIGHT " 3 "HOST" 2 "LEFT" 1 "LEFT_LEFT" 0 "UNKNOWN" ;
VAL_ 1221 ObstacleOccluded 2 "Obstacle occluded" 1 "Obstacle not occluded" 0 "Default" ;
VAL_ 1216 CutInFlag 2 "close cut in" 1 "cut in" 0 "not cut in" ;
VAL_ 1212 CIPVFlag 1 "CIPV" 0 "not CIPV" ;
VAL_ 1212 MCPFlag 1 "MCP" 0 "not MCP" ;
VAL_ 1212 ObstacleBlinkerInfo 4 "Both" 3 "Right" 2 "Left" 1 "Off" 0 "Unavailable" ;
VAL_ 1212 ObstacleBrakeLights 1 "ON" 0 "OFF" ;
VAL_ 1212 ObstaclePositionType 9 "Center" 8 "RightCenter" 7 "LeftCenter" 6 "FrontRight" 5 "FrontCenter" 4 "FrontLeft" 3 "RearRight" 2 "RearCenter" 1 "RearLeft   " 0 "Unknown    " ;
VAL_ 1211 ObstacleValid 2 "older valid" 1 "new valid (detected this frame)" 0 "invalid Obstacle(default value)" ;
VAL_ 1211 ObstacleReplaced 1 "replaced in this frame" 0 "not replaced in this frame" ;
VAL_ 1211 ObstacleMotionCategory 13 "ONCOMING" 12 "PRECEEDING" 11 "MOVING" 10 "RTAP" 9 "LTAP" 8 "CROSSING" 7 "MOVING_OUT" 6 "MOVING_IN" 5 "CLOSE_CUT_IN" 4 "PASSING_OUT" 3 "PASSING_IN" 2 "PASSING" 1 "UNDEFINED" 0 "INVALID" ;
VAL_ 1211 ObstacleMotionStatus 5 "MOVING SLOWLY" 4 "STOPPED" 3 "STATIONARY" 2 "MOVING" 1 "UNKNOWN" 0 "INVALID" ;
VAL_ 1211 ObstacleMeasuringStatus 2 "PREDICTED" 1 "MEASURED" 0 "INVALID" ;
VAL_ 1211 ObstacleClass 4 "GENERAL_OBJECT(reserved)" 3 "CYCLIST" 2 "PEDESTRIAN" 1 "VEHICLE" 0 "INVALID" ;
VAL_ 1211 VehicleSubType 7 "Lorry" 6 "Tiny_car" 5 "Special_vehicle" 4 "Motors(Tri-cycle)" 3 "Trucks" 2 "Small_Medium_Car" 1 "Bus" 0 "Unknown" ;
VAL_ 1211 PedSubType 2 "Child" 1 "Adult" 0 "Unknown" ;
VAL_ 1211 PedPos 5 "Sitter" 4 "Pedestrian" 3 "Lier" 2 "Cyclist" 1 "Bended" 0 "Unknown" ;
VAL_ 1211 PedOrientation 8 "right_back" 7 "right_front" 6 "right" 5 "left_back" 4 "left_front" 3 "left" 2 "front" 1 "back" 0 "Unknown" ;
VAL_ 1211 ObstacleLaneAssignment 5 "RIGHT_RIGHT" 4 "RIGHT " 3 "HOST" 2 "LEFT" 1 "LEFT_LEFT" 0 "UNKNOWN" ;
VAL_ 1211 ObstacleOccluded 2 "Obstacle occluded" 1 "Obstacle not occluded" 0 "Default" ;
VAL_ 1206 CutInFlag 2 "close cut in" 1 "cut in" 0 "not cut in" ;
VAL_ 1202 CIPVFlag 1 "CIPV" 0 "not CIPV" ;
VAL_ 1202 MCPFlag 1 "MCP" 0 "not MCP" ;
VAL_ 1202 ObstacleBlinkerInfo 4 "Both" 3 "Right" 2 "Left" 1 "Off" 0 "Unavailable" ;
VAL_ 1202 ObstacleBrakeLights 1 "ON" 0 "OFF" ;
VAL_ 1202 ObstaclePositionType 9 "Center" 8 "RightCenter" 7 "LeftCenter" 6 "FrontRight" 5 "FrontCenter" 4 "FrontLeft" 3 "RearRight" 2 "RearCenter" 1 "RearLeft   " 0 "Unknown    " ;
VAL_ 1201 ObstacleValid 2 "older valid" 1 "new valid (detected this frame)" 0 "invalid Obstacle(default value)" ;
VAL_ 1201 ObstacleReplaced 1 "replaced in this frame" 0 "not replaced in this frame" ;
VAL_ 1201 ObstacleMotionCategory 13 "ONCOMING" 12 "PRECEEDING" 11 "MOVING" 10 "RTAP" 9 "LTAP" 8 "CROSSING" 7 "MOVING_OUT" 6 "MOVING_IN" 5 "CLOSE_CUT_IN" 4 "PASSING_OUT" 3 "PASSING_IN" 2 "PASSING" 1 "UNDEFINED" 0 "INVALID" ;
VAL_ 1201 ObstacleMotionStatus 5 "MOVING SLOWLY" 4 "STOPPED" 3 "STATIONARY" 2 "MOVING" 1 "UNKNOWN" 0 "INVALID" ;
VAL_ 1201 ObstacleMeasuringStatus 2 "PREDICTED" 1 "MEASURED" 0 "INVALID" ;
VAL_ 1201 ObstacleClass 4 "GENERAL_OBJECT(reserved)" 3 "CYCLIST" 2 "PEDESTRIAN" 1 "VEHICLE" 0 "INVALID" ;
VAL_ 1201 VehicleSubType 7 "Lorry" 6 "Tiny_car" 5 "Special_vehicle" 4 "Motors(Tri-cycle)" 3 "Trucks" 2 "Small_Medium_Car" 1 "Bus" 0 "Unknown" ;
VAL_ 1201 PedSubType 2 "Child" 1 "Adult" 0 "Unknown" ;
VAL_ 1201 PedPos 5 "Sitter" 4 "Pedestrian" 3 "Lier" 2 "Cyclist" 1 "Bended" 0 "Unknown" ;
VAL_ 1201 PedOrientation 8 "right_back" 7 "right_front" 6 "right" 5 "left_back" 4 "left_front" 3 "left" 2 "front" 1 "back" 0 "Unknown" ;
VAL_ 1201 ObstacleLaneAssignment 5 "RIGHT_RIGHT" 4 "RIGHT " 3 "HOST" 2 "LEFT" 1 "LEFT_LEFT" 0 "UNKNOWN" ;
VAL_ 1201 ObstacleOccluded 2 "Obstacle occluded" 1 "Obstacle not occluded" 0 "Default" ;
VAL_ 1196 CutInFlag 2 "close cut in" 1 "cut in" 0 "not cut in" ;
VAL_ 1192 CIPVFlag 1 "CIPV" 0 "not CIPV" ;
VAL_ 1192 MCPFlag 1 "MCP" 0 "not MCP" ;
VAL_ 1192 ObstacleBlinkerInfo 4 "Both" 3 "Right" 2 "Left" 1 "Off" 0 "Unavailable" ;
VAL_ 1192 ObstacleBrakeLights 1 "ON" 0 "OFF" ;
VAL_ 1192 ObstaclePositionType 9 "Center" 8 "RightCenter" 7 "LeftCenter" 6 "FrontRight" 5 "FrontCenter" 4 "FrontLeft" 3 "RearRight" 2 "RearCenter" 1 "RearLeft   " 0 "Unknown    " ;
VAL_ 1191 ObstacleValid 2 "older valid" 1 "new valid (detected this frame)" 0 "invalid Obstacle(default value)" ;
VAL_ 1191 ObstacleReplaced 1 "replaced in this frame" 0 "not replaced in this frame" ;
VAL_ 1191 ObstacleMotionCategory 13 "ONCOMING" 12 "PRECEEDING" 11 "MOVING" 10 "RTAP" 9 "LTAP" 8 "CROSSING" 7 "MOVING_OUT" 6 "MOVING_IN" 5 "CLOSE_CUT_IN" 4 "PASSING_OUT" 3 "PASSING_IN" 2 "PASSING" 1 "UNDEFINED" 0 "INVALID" ;
VAL_ 1191 ObstacleMotionStatus 5 "MOVING SLOWLY" 4 "STOPPED" 3 "STATIONARY" 2 "MOVING" 1 "UNKNOWN" 0 "INVALID" ;
VAL_ 1191 ObstacleMeasuringStatus 2 "PREDICTED" 1 "MEASURED" 0 "INVALID" ;
VAL_ 1191 ObstacleClass 4 "GENERAL_OBJECT(reserved)" 3 "CYCLIST" 2 "PEDESTRIAN" 1 "VEHICLE" 0 "INVALID" ;
VAL_ 1191 VehicleSubType 7 "Lorry" 6 "Tiny_car" 5 "Special_vehicle" 4 "Motors(Tri-cycle)" 3 "Trucks" 2 "Small_Medium_Car" 1 "Bus" 0 "Unknown" ;
VAL_ 1191 PedSubType 2 "Child" 1 "Adult" 0 "Unknown" ;
VAL_ 1191 PedPos 5 "Sitter" 4 "Pedestrian" 3 "Lier" 2 "Cyclist" 1 "Bended" 0 "Unknown" ;
VAL_ 1191 PedOrientation 8 "right_back" 7 "right_front" 6 "right" 5 "left_back" 4 "left_front" 3 "left" 2 "front" 1 "back" 0 "Unknown" ;
VAL_ 1191 ObstacleLaneAssignment 5 "RIGHT_RIGHT" 4 "RIGHT " 3 "HOST" 2 "LEFT" 1 "LEFT_LEFT" 0 "UNKNOWN" ;
VAL_ 1191 ObstacleOccluded 2 "Obstacle occluded" 1 "Obstacle not occluded" 0 "Default" ;
VAL_ 1186 CutInFlag 2 "close cut in" 1 "cut in" 0 "not cut in" ;
VAL_ 1182 CIPVFlag 1 "CIPV" 0 "not CIPV" ;
VAL_ 1182 MCPFlag 1 "MCP" 0 "not MCP" ;
VAL_ 1182 ObstacleBlinkerInfo 4 "Both" 3 "Right" 2 "Left" 1 "Off" 0 "Unavailable" ;
VAL_ 1182 ObstacleBrakeLights 1 "ON" 0 "OFF" ;
VAL_ 1182 ObstaclePositionType 9 "Center" 8 "RightCenter" 7 "LeftCenter" 6 "FrontRight" 5 "FrontCenter" 4 "FrontLeft" 3 "RearRight" 2 "RearCenter" 1 "RearLeft   " 0 "Unknown    " ;
VAL_ 1181 ObstacleValid 2 "older valid" 1 "new valid (detected this frame)" 0 "invalid Obstacle(default value)" ;
VAL_ 1181 ObstacleReplaced 1 "replaced in this frame" 0 "not replaced in this frame" ;
VAL_ 1181 ObstacleMotionCategory 13 "ONCOMING" 12 "PRECEEDING" 11 "MOVING" 10 "RTAP" 9 "LTAP" 8 "CROSSING" 7 "MOVING_OUT" 6 "MOVING_IN" 5 "CLOSE_CUT_IN" 4 "PASSING_OUT" 3 "PASSING_IN" 2 "PASSING" 1 "UNDEFINED" 0 "INVALID" ;
VAL_ 1181 ObstacleMotionStatus 5 "MOVING SLOWLY" 4 "STOPPED" 3 "STATIONARY" 2 "MOVING" 1 "UNKNOWN" 0 "INVALID" ;
VAL_ 1181 ObstacleMeasuringStatus 2 "PREDICTED" 1 "MEASURED" 0 "INVALID" ;
VAL_ 1181 ObstacleClass 4 "GENERAL_OBJECT(reserved)" 3 "CYCLIST" 2 "PEDESTRIAN" 1 "VEHICLE" 0 "INVALID" ;
VAL_ 1181 VehicleSubType 7 "Lorry" 6 "Tiny_car" 5 "Special_vehicle" 4 "Motors(Tri-cycle)" 3 "Trucks" 2 "Small_Medium_Car" 1 "Bus" 0 "Unknown" ;
VAL_ 1181 PedSubType 2 "Child" 1 "Adult" 0 "Unknown" ;
VAL_ 1181 PedPos 5 "Sitter" 4 "Pedestrian" 3 "Lier" 2 "Cyclist" 1 "Bended" 0 "Unknown" ;
VAL_ 1181 PedOrientation 8 "right_back" 7 "right_front" 6 "right" 5 "left_back" 4 "left_front" 3 "left" 2 "front" 1 "back" 0 "Unknown" ;
VAL_ 1181 ObstacleLaneAssignment 5 "RIGHT_RIGHT" 4 "RIGHT " 3 "HOST" 2 "LEFT" 1 "LEFT_LEFT" 0 "UNKNOWN" ;
VAL_ 1181 ObstacleOccluded 2 "Obstacle occluded" 1 "Obstacle not occluded" 0 "Default" ;
VAL_ 1176 CutInFlag 2 "close cut in" 1 "cut in" 0 "not cut in" ;
VAL_ 1172 CIPVFlag 1 "CIPV" 0 "not CIPV" ;
VAL_ 1172 MCPFlag 1 "MCP" 0 "not MCP" ;
VAL_ 1172 ObstacleBlinkerInfo 4 "Both" 3 "Right" 2 "Left" 1 "Off" 0 "Unavailable" ;
VAL_ 1172 ObstacleBrakeLights 1 "ON" 0 "OFF" ;
VAL_ 1172 ObstaclePositionType 9 "Center" 8 "RightCenter" 7 "LeftCenter" 6 "FrontRight" 5 "FrontCenter" 4 "FrontLeft" 3 "RearRight" 2 "RearCenter" 1 "RearLeft   " 0 "Unknown    " ;
VAL_ 1171 ObstacleValid 2 "older valid" 1 "new valid (detected this frame)" 0 "invalid Obstacle(default value)" ;
VAL_ 1171 ObstacleReplaced 1 "replaced in this frame" 0 "not replaced in this frame" ;
VAL_ 1171 ObstacleMotionCategory 13 "ONCOMING" 12 "PRECEEDING" 11 "MOVING" 10 "RTAP" 9 "LTAP" 8 "CROSSING" 7 "MOVING_OUT" 6 "MOVING_IN" 5 "CLOSE_CUT_IN" 4 "PASSING_OUT" 3 "PASSING_IN" 2 "PASSING" 1 "UNDEFINED" 0 "INVALID" ;
VAL_ 1171 ObstacleMotionStatus 5 "MOVING SLOWLY" 4 "STOPPED" 3 "STATIONARY" 2 "MOVING" 1 "UNKNOWN" 0 "INVALID" ;
VAL_ 1171 ObstacleMeasuringStatus 2 "PREDICTED" 1 "MEASURED" 0 "INVALID" ;
VAL_ 1171 ObstacleClass 4 "GENERAL_OBJECT(reserved)" 3 "CYCLIST" 2 "PEDESTRIAN" 1 "VEHICLE" 0 "INVALID" ;
VAL_ 1171 VehicleSubType 7 "Lorry" 6 "Tiny_car" 5 "Special_vehicle" 4 "Motors(Tri-cycle)" 3 "Trucks" 2 "Small_Medium_Car" 1 "Bus" 0 "Unknown" ;
VAL_ 1171 PedSubType 2 "Child" 1 "Adult" 0 "Unknown" ;
VAL_ 1171 PedPos 5 "Sitter" 4 "Pedestrian" 3 "Lier" 2 "Cyclist" 1 "Bended" 0 "Unknown" ;
VAL_ 1171 PedOrientation 8 "right_back" 7 "right_front" 6 "right" 5 "left_back" 4 "left_front" 3 "left" 2 "front" 1 "back" 0 "Unknown" ;
VAL_ 1171 ObstacleLaneAssignment 5 "RIGHT_RIGHT" 4 "RIGHT " 3 "HOST" 2 "LEFT" 1 "LEFT_LEFT" 0 "UNKNOWN" ;
VAL_ 1171 ObstacleOccluded 2 "Obstacle occluded" 1 "Obstacle not occluded" 0 "Default" ;
VAL_ 1166 CutInFlag 2 "close cut in" 1 "cut in" 0 "not cut in" ;
VAL_ 1162 CIPVFlag 1 "CIPV" 0 "not CIPV" ;
VAL_ 1162 MCPFlag 1 "MCP" 0 "not MCP" ;
VAL_ 1162 ObstacleBlinkerInfo 4 "Both" 3 "Right" 2 "Left" 1 "Off" 0 "Unavailable" ;
VAL_ 1162 ObstacleBrakeLights 1 "ON" 0 "OFF" ;
VAL_ 1162 ObstaclePositionType 9 "Center" 8 "RightCenter" 7 "LeftCenter" 6 "FrontRight" 5 "FrontCenter" 4 "FrontLeft" 3 "RearRight" 2 "RearCenter" 1 "RearLeft   " 0 "Unknown    " ;
VAL_ 1161 ObstacleValid 2 "older valid" 1 "new valid (detected this frame)" 0 "invalid Obstacle(default value)" ;
VAL_ 1161 ObstacleReplaced 1 "replaced in this frame" 0 "not replaced in this frame" ;
VAL_ 1161 ObstacleMotionCategory 13 "ONCOMING" 12 "PRECEEDING" 11 "MOVING" 10 "RTAP" 9 "LTAP" 8 "CROSSING" 7 "MOVING_OUT" 6 "MOVING_IN" 5 "CLOSE_CUT_IN" 4 "PASSING_OUT" 3 "PASSING_IN" 2 "PASSING" 1 "UNDEFINED" 0 "INVALID" ;
VAL_ 1161 ObstacleMotionStatus 5 "MOVING SLOWLY" 4 "STOPPED" 3 "STATIONARY" 2 "MOVING" 1 "UNKNOWN" 0 "INVALID" ;
VAL_ 1161 ObstacleMeasuringStatus 2 "PREDICTED" 1 "MEASURED" 0 "INVALID" ;
VAL_ 1161 ObstacleClass 4 "GENERAL_OBJECT(reserved)" 3 "CYCLIST" 2 "PEDESTRIAN" 1 "VEHICLE" 0 "INVALID" ;
VAL_ 1161 VehicleSubType 7 "Lorry" 6 "Tiny_car" 5 "Special_vehicle" 4 "Motors(Tri-cycle)" 3 "Trucks" 2 "Small_Medium_Car" 1 "Bus" 0 "Unknown" ;
VAL_ 1161 PedSubType 2 "Child" 1 "Adult" 0 "Unknown" ;
VAL_ 1161 PedPos 5 "Sitter" 4 "Pedestrian" 3 "Lier" 2 "Cyclist" 1 "Bended" 0 "Unknown" ;
VAL_ 1161 PedOrientation 8 "right_back" 7 "right_front" 6 "right" 5 "left_back" 4 "left_front" 3 "left" 2 "front" 1 "back" 0 "Unknown" ;
VAL_ 1161 ObstacleLaneAssignment 5 "RIGHT_RIGHT" 4 "RIGHT " 3 "HOST" 2 "LEFT" 1 "LEFT_LEFT" 0 "UNKNOWN" ;
VAL_ 1161 ObstacleOccluded 2 "Obstacle occluded" 1 "Obstacle not occluded" 0 "Default" ;
VAL_ 1156 CutInFlag 2 "close cut in" 1 "cut in" 0 "not cut in" ;
VAL_ 1152 CIPVFlag 1 "CIPV" 0 "not CIPV" ;
VAL_ 1152 MCPFlag 1 "MCP" 0 "not MCP" ;
VAL_ 1152 ObstacleBlinkerInfo 4 "Both" 3 "Right" 2 "Left" 1 "Off" 0 "Unavailable" ;
VAL_ 1152 ObstacleBrakeLights 1 "ON" 0 "OFF" ;
VAL_ 1152 ObstaclePositionType 9 "Center" 8 "RightCenter" 7 "LeftCenter" 6 "FrontRight" 5 "FrontCenter" 4 "FrontLeft" 3 "RearRight" 2 "RearCenter" 1 "RearLeft   " 0 "Unknown    " ;
VAL_ 1151 ObstacleValid 2 "older valid" 1 "new valid (detected this frame)" 0 "invalid Obstacle(default value)" ;
VAL_ 1151 ObstacleReplaced 1 "replaced in this frame" 0 "not replaced in this frame" ;
VAL_ 1151 ObstacleMotionCategory 13 "ONCOMING" 12 "PRECEEDING" 11 "MOVING" 10 "RTAP" 9 "LTAP" 8 "CROSSING" 7 "MOVING_OUT" 6 "MOVING_IN" 5 "CLOSE_CUT_IN" 4 "PASSING_OUT" 3 "PASSING_IN" 2 "PASSING" 1 "UNDEFINED" 0 "INVALID" ;
VAL_ 1151 ObstacleMotionStatus 5 "MOVING SLOWLY" 4 "STOPPED" 3 "STATIONARY" 2 "MOVING" 1 "UNKNOWN" 0 "INVALID" ;
VAL_ 1151 ObstacleMeasuringStatus 2 "PREDICTED" 1 "MEASURED" 0 "INVALID" ;
VAL_ 1151 ObstacleClass 4 "GENERAL_OBJECT(reserved)" 3 "CYCLIST" 2 "PEDESTRIAN" 1 "VEHICLE" 0 "INVALID" ;
VAL_ 1151 VehicleSubType 7 "Lorry" 6 "Tiny_car" 5 "Special_vehicle" 4 "Motors(Tri-cycle)" 3 "Trucks" 2 "Small_Medium_Car" 1 "Bus" 0 "Unknown" ;
VAL_ 1151 PedSubType 2 "Child" 1 "Adult" 0 "Unknown" ;
VAL_ 1151 PedPos 5 "Sitter" 4 "Pedestrian" 3 "Lier" 2 "Cyclist" 1 "Bended" 0 "Unknown" ;
VAL_ 1151 PedOrientation 8 "right_back" 7 "right_front" 6 "right" 5 "left_back" 4 "left_front" 3 "left" 2 "front" 1 "back" 0 "Unknown" ;
VAL_ 1151 ObstacleLaneAssignment 5 "RIGHT_RIGHT" 4 "RIGHT " 3 "HOST" 2 "LEFT" 1 "LEFT_LEFT" 0 "UNKNOWN" ;
VAL_ 1151 ObstacleOccluded 2 "Obstacle occluded" 1 "Obstacle not occluded" 0 "Default" ;
VAL_ 1146 CutInFlag 2 "close cut in" 1 "cut in" 0 "not cut in" ;
VAL_ 1142 CIPVFlag 1 "CIPV" 0 "not CIPV" ;
VAL_ 1142 MCPFlag 1 "MCP" 0 "not MCP" ;
VAL_ 1142 ObstacleBlinkerInfo 4 "Both" 3 "Right" 2 "Left" 1 "Off" 0 "Unavailable" ;
VAL_ 1142 ObstacleBrakeLights 1 "ON" 0 "OFF" ;
VAL_ 1142 ObstaclePositionType 9 "Center" 8 "RightCenter" 7 "LeftCenter" 6 "FrontRight" 5 "FrontCenter" 4 "FrontLeft" 3 "RearRight" 2 "RearCenter" 1 "RearLeft   " 0 "Unknown    " ;
VAL_ 1141 ObstacleValid 2 "older valid" 1 "new valid (detected this frame)" 0 "invalid Obstacle(default value)" ;
VAL_ 1141 ObstacleReplaced 1 "replaced in this frame" 0 "not replaced in this frame" ;
VAL_ 1141 ObstacleMotionCategory 13 "ONCOMING" 12 "PRECEEDING" 11 "MOVING" 10 "RTAP" 9 "LTAP" 8 "CROSSING" 7 "MOVING_OUT" 6 "MOVING_IN" 5 "CLOSE_CUT_IN" 4 "PASSING_OUT" 3 "PASSING_IN" 2 "PASSING" 1 "UNDEFINED" 0 "INVALID" ;
VAL_ 1141 ObstacleMotionStatus 5 "MOVING SLOWLY" 4 "STOPPED" 3 "STATIONARY" 2 "MOVING" 1 "UNKNOWN" 0 "INVALID" ;
VAL_ 1141 ObstacleMeasuringStatus 2 "PREDICTED" 1 "MEASURED" 0 "INVALID" ;
VAL_ 1141 ObstacleClass 4 "GENERAL_OBJECT(reserved)" 3 "CYCLIST" 2 "PEDESTRIAN" 1 "VEHICLE" 0 "INVALID" ;
VAL_ 1141 VehicleSubType 7 "Lorry" 6 "Tiny_car" 5 "Special_vehicle" 4 "Motors(Tri-cycle)" 3 "Trucks" 2 "Small_Medium_Car" 1 "Bus" 0 "Unknown" ;
VAL_ 1141 PedSubType 2 "Child" 1 "Adult" 0 "Unknown" ;
VAL_ 1141 PedPos 5 "Sitter" 4 "Pedestrian" 3 "Lier" 2 "Cyclist" 1 "Bended" 0 "Unknown" ;
VAL_ 1141 PedOrientation 8 "right_back" 7 "right_front" 6 "right" 5 "left_back" 4 "left_front" 3 "left" 2 "front" 1 "back" 0 "Unknown" ;
VAL_ 1141 ObstacleLaneAssignment 5 "RIGHT_RIGHT" 4 "RIGHT " 3 "HOST" 2 "LEFT" 1 "LEFT_LEFT" 0 "UNKNOWN" ;
VAL_ 1141 ObstacleOccluded 2 "Obstacle occluded" 1 "Obstacle not occluded" 0 "Default" ;
VAL_ 1136 CutInFlag 2 "close cut in" 1 "cut in" 0 "not cut in" ;
VAL_ 1132 CIPVFlag 1 "CIPV" 0 "not CIPV" ;
VAL_ 1132 MCPFlag 1 "MCP" 0 "not MCP" ;
VAL_ 1132 ObstacleBlinkerInfo 4 "Both" 3 "Right" 2 "Left" 1 "Off" 0 "Unavailable" ;
VAL_ 1132 ObstacleBrakeLights 1 "ON" 0 "OFF" ;
VAL_ 1132 ObstaclePositionType 9 "Center" 8 "RightCenter" 7 "LeftCenter" 6 "FrontRight" 5 "FrontCenter" 4 "FrontLeft" 3 "RearRight" 2 "RearCenter" 1 "RearLeft   " 0 "Unknown    " ;
